AUTOSAR XML (schema 4-2-1)
standard types defined: boolean, uint16, uint32, uint8
package /VehicleProject
  system System
package /TP
  can tp config FD1_CAN: communication-cluster=FD1_CAN, can-tp-ecu{cycle-time-main-function=0.005, ecu-instance=PSCM_FD}
    can tp channel TPCH: channel-id=0, channel-mode=FULL-DUPLEX-MODE
    can-tp-connection addressing-format=STANDARD, can-tp-channel=TPCH, data-pdu=TesterFunctionalReq_FD1_Tp_oFD1_CAN, receiver=TN_PSCM_FD_FD, ta-type=FUNCTIONAL-CAN-FD, tp-sdu=TesterFunctionalReq_FD1_oFD1_CAN, transmitter=TN_TSTR_FD:
      ident TesterFunctionalReq_FD1_FD_oTN_TSTR_FD
    can-tp-connection addressing-format=STANDARD, can-tp-channel=TPCH, data-pdu=TesterFunctionalReq_FD1_Tp_oFD1_CAN_20, receiver=TN_PSCM_FD, ta-type=FUNCTIONAL, tp-sdu=TesterFunctionalReq_FD1_oFD1_CAN_20, transmitter=TN_TSTR:
      ident TesterFunctionalReq_FD1_oTN_TSTR
    can-tp-connection addressing-format=STANDARD, can-tp-channel=TPCH, data-pdu=TesterPhysicalReqPSCM_FD1_Tp_oFD1_CAN_20, flow-control-pdu=TesterPhysicalResPSCM_FD1_Tp_oFD1_CAN_20, receiver=TN_PSCM_FD, ta-type=PHYSICAL, tp-sdu=TesterPhysicalReqPSCM_FD1_oFD1_CAN_20, transmitter=TN_TSTR:
      ident TesterPhysicalReqPSCM_FD1_oTN_PSCM_FD
    can-tp-connection addressing-format=STANDARD, can-tp-channel=TPCH, data-pdu=TesterPhysicalReqPSCM_FD1_Tp_oFD1_CAN, flow-control-pdu=TesterPhysicalResPSCM_FD1_Tp_oFD1_CAN, receiver=TN_PSCM_FD_FD, ta-type=PHYSICAL-CAN-FD, tp-sdu=TesterPhysicalReqPSCM_FD1_oFD1_CAN, transmitter=TN_TSTR_FD:
      ident TesterPhysicalReqPSCM_FD1_oTN_PSCM_FD_FD
    can-tp-connection addressing-format=STANDARD, can-tp-channel=TPCH, data-pdu=TesterPhysicalResPSCM_FD1_Tp_oFD1_CAN_20, flow-control-pdu=TesterPhysicalReqPSCM_FD1_Tp_oFD1_CAN_20, receiver=TN_TSTR, ta-type=PHYSICAL, tp-sdu=TesterPhysicalResPSCM_FD1_oFD1_CAN_20, transmitter=TN_PSCM_FD:
      ident TesterPhysicalResPSCM_FD1_oTN_PSCM_FD
    can-tp-connection addressing-format=STANDARD, can-tp-channel=TPCH, data-pdu=TesterPhysicalResPSCM_FD1_Tp_oFD1_CAN, flow-control-pdu=TesterPhysicalReqPSCM_FD1_Tp_oFD1_CAN, receiver=TN_TSTR_FD, ta-type=PHYSICAL-CAN-FD, tp-sdu=TesterPhysicalResPSCM_FD1_oFD1_CAN, transmitter=TN_PSCM_FD_FD:
      ident TesterPhysicalResPSCM_FD1_oTN_PSCM_FD_FD
    4 x can tp node:
      TN_PSCM_FD: connector=CN_FD1_CAN
      TN_PSCM_FD_FD: connector=CN_FD1_CAN
      TN_TSTR
      TN_TSTR_FD
package /Cluster
  can cluster FD1_CAN: baudrate=500000, protocol-name=CAN, can-fd-baudrate=500000  # FD1_CAN_P702_GASD_MY21_V05 | New CAN FD network
    can physical channel CHNL: comm-connectors=CN_FD1_CAN
      frame ABS_BrkBst_Data_FD1_oFD1_CAN: id 0x4B0, to PSCM_FD, frame-length=8, can-addressing-mode=STANDARD, can-frame-rx-behavior=ANY, can-frame-tx-behavior=CAN-FD
        pdu ABS_BrkBst_Data_FD1_oFD1_CAN: length=8, minimum-delay=0.01, transmission-mode-false-timing=cyclic-timing={time-offset=0, time-period=0.02}, transmission-mode-true-timing=cyclic-timing={time-offset=0, time-period=0.02}, unused-bit-pattern=0
          signal YawStabilityIndex_oABS_BrkBst_Data_FD1_oFD1_CAN: start 0, 9 bit, big-endian, init-value=256, base-type=uint16, compu {510=Cx1FE_NoDataExists, 511=Cx1FF_Fault, phys=raw-256 for raw 0..511; unit %}, unit=%, transfer-property=PENDING, to PSCM_FD
      frame ActiveFrontStrg_Stat2_FD1_oFD1_CAN: id 0x8A, to PSCM_FD, frame-length=8, can-addressing-mode=STANDARD, can-frame-rx-behavior=ANY, can-frame-tx-behavior=CAN-FD
        pdu ActiveFrontStrg_Stat2_FD1_oFD1_CAN: length=8, minimum-delay=0.02, unused-bit-pattern=0
          signal SteWhlRelCalib_An_Sns_oActiveFrontStrg_Stat2_FD1_oFD1_CAN: start 15, 15 bit, big-endian, init-value=0, base-type=uint16, compu {32766=Cx7FFE_NoDataExists, 32767=Cx7FFF_Fault, phys=raw*0.1-1600 for raw 0..32767; unit deg} "Source signal range: [0,32765]", unit=deg, transfer-property=PENDING, to PSCM_FD  # Signal is not transmitted on vehicles where PSCM is transmitting the message that contains this signal. Signal data set to 0x0 for ABS only vehicle option content
      frame APIM_Send_Signals_2_FD1_oFD1_CAN: id 0x215, to PSCM_FD, frame-length=8, can-addressing-mode=STANDARD, can-frame-rx-behavior=ANY, can-frame-tx-behavior=CAN-FD
        pdu APIM_Send_Signals_2_FD1_oFD1_CAN: length=8, minimum-delay=0.02, unused-bit-pattern=0
          signal TrlrAidMde_D_Rq_oAPIM_Send_Signals_2_FD1_oFD1_CAN: start 5, 2 bit, big-endian, init-value=0, base-type=uint8, compu {0..3=RANGE, 0=Cx0_NoRequest, 1=Cx1_Mode_1, 2=Cx2_Mode_2, 3=Cx3_Mode_3; unit SED}, unit=SED, transfer-property=PENDING, to PSCM_FD
      frame APIM_Send_Signals1_FD1_oFD1_CAN: id 0x3F1, to PSCM_FD, frame-length=8, can-addressing-mode=STANDARD, can-frame-rx-behavior=ANY, can-frame-tx-behavior=CAN-FD  # APIM Tx
        pdu APIM_Send_Signals1_FD1_oFD1_CAN: length=8, minimum-delay=0.02, unused-bit-pattern=0
          signal TrlrAidCancl_B_Rq_oAPIM_Send_Signals1_FD1_oFD1_CAN: start 48, 1 bit, big-endian, init-value=0, base-type=boolean, compu {0..1=RANGE, 0=Cx0_Null, 1=Cx1_Cancel; unit SED}, unit=SED, transfer-property=PENDING, to PSCM_FD
      frame Body_Info_4_FD1_oFD1_CAN: id 0x242, to PSCM_FD, frame-length=8, can-addressing-mode=STANDARD, can-frame-rx-behavior=ANY, can-frame-tx-behavior=CAN-FD
        pdu Body_Info_4_FD1_oFD1_CAN: length=8, minimum-delay=0.02, unused-bit-pattern=0
          signal BattULo_U_Actl_oBody_Info_4_FD1_oFD1_CAN: start 39, 8 bit, big-endian, init-value=255, base-type=uint8, compu {255=CxFF_Fault, phys=raw*0.0625 for raw 0..255; unit volt} "Source signal range: [0,254]", unit=volt, transfer-property=PENDING, to PSCM_FD
      frame BodyInfo_3_FD1_oFD1_CAN: id 0x3B3, to PSCM_FD, frame-length=8, can-addressing-mode=STANDARD, can-frame-rx-behavior=ANY, can-frame-tx-behavior=CAN-FD
        pdu BodyInfo_3_FD1_oFD1_CAN: length=8, minimum-delay=0.02, unused-bit-pattern=0
          signal Ignition_Status_oBodyInfo_3_FD1_oFD1_CAN: start 7, 4 bit, big-endian, init-value=0, base-type=uint8, compu {0..15=RANGE, 0=Cx0_Unknown, 1=Cx1_Off, 2=Cx2_Accessory, 4=Cx4_Run, 8=Cx8_Start, 15=CxF_Invalid; unit SED}, unit=SED, transfer-property=PENDING, to PSCM_FD
          signal LifeCycMde_D_Actl_oBodyInfo_3_FD1_oFD1_CAN: start 53, 4 bit, big-endian, init-value=0, base-type=uint8, compu {0..15=RANGE, 0=Cx0_Normal, 1=Cx1_Factory, 2=Cx2_NotUsed, 3=Cx3_Transport; unit SED}, unit=SED, transfer-property=PENDING, to PSCM_FD
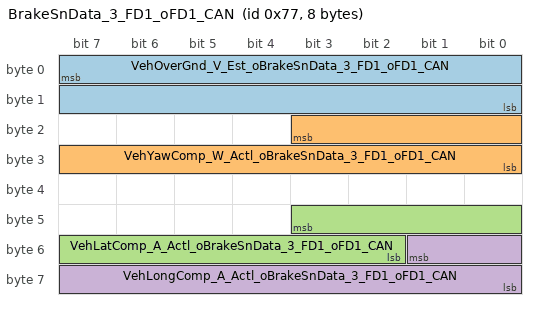
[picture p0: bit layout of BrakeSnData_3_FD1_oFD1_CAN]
      frame BrakeSnData_3_FD1_oFD1_CAN: id 0x77, to PSCM_FD, frame-length=8, can-addressing-mode=STANDARD, can-frame-rx-behavior=ANY, can-frame-tx-behavior=CAN-FD
        pdu BrakeSnData_3_FD1_oFD1_CAN: length=8, minimum-delay=0.01, transmission-mode-false-timing=cyclic-timing={time-offset=0, time-period=0.02}, transmission-mode-true-timing=cyclic-timing={time-offset=0, time-period=0.02}, unused-bit-pattern=0
          signal VehOverGnd_V_Est_oBrakeSnData_3_FD1_oFD1_CAN: start 7, 16 bit, big-endian, init-value=0, base-type=uint16, compu {65534=CxFFFE_Unknown, 65535=CxFFFF_Invalid, phys=raw*0.01 for raw 0..65535; unit kph} "Source signal range: [0,65533]", unit=kph, transfer-property=PENDING, to PSCM_FD
          signal VehYawComp_W_Actl_oBrakeSnData_3_FD1_oFD1_CAN: start 19, 12 bit, big-endian, init-value=4094, base-type=uint16, compu {4094=CxFFE_NoDataExists, 4095=CxFFF_Fault, phys=raw*0.03663-75 for raw 0..4095; unit deg/s} "Source signal range: [0,4093]", unit=deg/s, transfer-property=PENDING, to PSCM_FD
          signal VehLatComp_A_Actl_oBrakeSnData_3_FD1_oFD1_CAN: start 43, 10 bit, big-endian, init-value=1022, base-type=uint16, compu {1022=Cx3FE_NoDataExists, 1023=Cx3FF_Fault, phys=raw*0.035-17.9 for raw 0..1023; unit m/s^2} "Source signal range: [0,1021]", unit=m/s^2, transfer-property=PENDING, to PSCM_FD
          signal VehLongComp_A_Actl_oBrakeSnData_3_FD1_oFD1_CAN: start 49, 10 bit, big-endian, init-value=1022, base-type=uint16, compu {1022=Cx3FE_NoDataExists, 1023=Cx3FF_Fault, phys=raw*0.035-17.9 for raw 0..1023; unit m/s^2} "Source signal range: [0,1021]", unit=m/s^2, transfer-property=PENDING, to PSCM_FD
      frame BrakeSnData_4_FD1_oFD1_CAN: id 0x7D, to PSCM_FD, frame-length=8, can-addressing-mode=STANDARD, can-frame-rx-behavior=ANY, can-frame-tx-behavior=CAN-FD
        pdu BrakeSnData_4_FD1_oFD1_CAN: length=8, minimum-delay=0.01, transmission-mode-false-timing=cyclic-timing={time-offset=0, time-period=0.02}, transmission-mode-true-timing=cyclic-timing={time-offset=0, time-period=0.02}, unused-bit-pattern=0
          signal BrkTot_Tq_Actl_oBrakeSnData_4_FD1_oFD1_CAN: start 27, 13 bit, big-endian, init-value=0, base-type=uint16, compu {8190=Cx1FFE_Unknown, 8191=Cx1FFF_Fault, phys=raw*4 for raw 0..8191; unit Nm} "Source signal range: [0,8189]", unit=Nm, transfer-property=PENDING, to PSCM_FD
          signal VehVertComp_A_Actl_oBrakeSnData_4_FD1_oFD1_CAN: start 45, 10 bit, big-endian, init-value=1022, base-type=uint16, compu {1022=Cx3FE_NoDataExists, 1023=Cx3FF_Fault, phys=raw*0.035-17.9 for raw 0..1023; unit m/s^2} "Source signal range: [0,1021]", unit=m/s^2, transfer-property=PENDING, to PSCM_FD
      frame BrakeSnData_5_FD1_oFD1_CAN: id 0x76, to PSCM_FD, frame-length=8, can-addressing-mode=STANDARD, can-frame-rx-behavior=ANY, can-frame-tx-behavior=CAN-FD
        pdu BrakeSnData_5_FD1_oFD1_CAN: length=8, minimum-delay=0.02, transmission-mode-false-timing={cyclic-timing={time-offset=0, time-period=0.5}, event-controlled-timing={number-of-repetitions=0, repetition-period=0}}, transmission-mode-true-timing={cyclic-timing={time-offset=0, time-period=0.5}, event-controlled-timing={number-of-repetitions=0, repetition-period=0}}, unused-bit-pattern=0
          signal DrvSte_D_Stat_oBrakeSnData_5_FD1_oFD1_CAN: start 19, 4 bit, big-endian, init-value=0, base-type=uint8, compu {0..15=RANGE, 0=Cx0_DSR_Deactivated, 1=Cx1_DSR_Request_Not_Applicable, 2=Cx2_EPAS_Comm_Disturbed, 3=Cx3_DSR_in_Normal_Idle_Mode, 4=Cx4_Ignition_Off, 5=Cx5_Request_Active, 6=Cx6_NotUsed1, 7=Cx7_NotUsed2, 8=Cx8_NotUsed3, 9=Cx9_NotUsed4, 10=CxA_NotUsed5, 11=CxB_NotUsed6, 12=CxC_NotUsed7, 13=CxD_NotUsed8, 14=CxE_NotUsed9, 15=CxF_NotUsed10; unit SED}, unit=SED, transfer-property=TRIGGERED-ON-CHANGE-WITHOUT-REPETITION, to PSCM_FD
          signal DrvSte_Tq_Rq_oBrakeSnData_5_FD1_oFD1_CAN: start 31, 8 bit, big-endian, init-value=128, base-type=uint8, compu {254=CxFE_Unknown, 255=CxFF_Invalid, phys=raw*0.0625-8 for raw 0..255; unit Nm} "Source signal range: [0,253]", unit=Nm, transfer-property=PENDING, to PSCM_FD
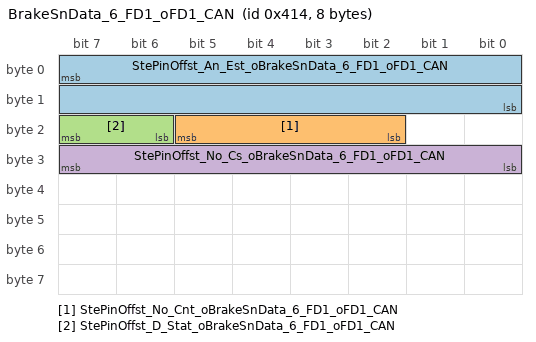
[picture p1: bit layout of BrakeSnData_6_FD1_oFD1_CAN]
      frame BrakeSnData_6_FD1_oFD1_CAN: id 0x414, to PSCM_FD, frame-length=8, can-addressing-mode=STANDARD, can-frame-rx-behavior=ANY, can-frame-tx-behavior=CAN-FD
        pdu BrakeSnData_6_FD1_oFD1_CAN: length=8, minimum-delay=0.02, transmission-mode-false-timing=cyclic-timing={time-offset=0, time-period=0.1}, transmission-mode-true-timing=cyclic-timing={time-offset=0, time-period=0.1}, unused-bit-pattern=0
          signal StePinOffst_An_Est_oBrakeSnData_6_FD1_oFD1_CAN: start 7, 16 bit, big-endian, init-value=65534, base-type=uint16, compu {65534=CxFFFE_NoDataExists, 65535=CxFFFF_Faulty, phys=raw*0.1-3200 for raw 0..65535; unit degrees} "Source signal range: [0,65533]", unit=degrees, transfer-property=PENDING, to PSCM_FD  # SASM will transmit these signals on vehicles with SASM and without PSCM. SCCM will not Tx this signal when SASM is present.
          signal StePinOffst_No_Cnt_oBrakeSnData_6_FD1_oFD1_CAN: start 21, 4 bit, big-endian, init-value=0, base-type=uint8, compu {0..15=RANGE; unit unitless}, unit=unitless, transfer-property=PENDING, to PSCM_FD
          signal StePinOffst_D_Stat_oBrakeSnData_6_FD1_oFD1_CAN: start 23, 2 bit, big-endian, init-value=0, base-type=uint8, compu {0..3=RANGE, 0=Cx0_OffsetNotCalculated, 1=Cx1_StoredOffset, 2=Cx2_CoarseOffset, 3=Cx3_FineOffset; unit SED}, unit=SED, transfer-property=PENDING, to PSCM_FD
          signal StePinOffst_No_Cs_oBrakeSnData_6_FD1_oFD1_CAN: start 31, 8 bit, big-endian, init-value=0, base-type=uint8, compu {0..255=RANGE; unit Unitless}, unit=Unitless, transfer-property=PENDING, to PSCM_FD  # Signal not transmitted on gas variants.
      frame BrakeSysFeatures_3_oFD1_CAN: id 0x41E, to PSCM_FD, frame-length=8, can-addressing-mode=STANDARD, can-frame-rx-behavior=ANY, can-frame-tx-behavior=CAN-FD
        pdu BrakeSysFeatures_3_oFD1_CAN: length=8, minimum-delay=0.02, transmission-mode-false-timing={cyclic-timing={time-offset=0, time-period=1}, event-controlled-timing={number-of-repetitions=0, repetition-period=0}}, transmission-mode-true-timing={cyclic-timing={time-offset=0, time-period=1}, event-controlled-timing={number-of-repetitions=0, repetition-period=0}}, unused-bit-pattern=0
          signal SelDrvMdeChassis2_D_Rq_oBrakeSysFeatures_3_oFD1_CAN: start 45, 5 bit, big-endian, init-value=0, base-type=uint8, compu {0..31=RANGE, 0=Cx00_NormalMode, 1=Cx01_NormalAdaptiveMode, 2=Cx02_EconomyMode, 3=Cx03_SportMode, 4=Cx04_SportAdaptiveMode, 5=Cx05_ComfortMode, 6=Cx06_ComfortAdaptiveMode, 7=Cx07_LowMuMode, 8=Cx08_MudAndRutsMode, 9=Cx09_SandMode, 10=Cx0A_RockCrawlMode, 11=Cx0B_TowHaulMode, 12=Cx0C_HighSpeedDesertMode, 13=Cx0D_TrackMode, 14=Cx0E_RoughRoadMode, 15=Cx0F_NotUsed2, 16=Cx10_NotUsed3, 17=Cx11_NotUsed4, 18=Cx12_NotUsed5, 19=Cx13_NotUsed6, 20=Cx14_NotUsed7, 21=Cx15_NotUsed8, 22=Cx16_NotUsed9, 23=Cx17_NotUsed10, 24=Cx18_NotUsed11, 25=Cx19_NotUsed12, 26=Cx1A_NotUsed13, 27=Cx1B_NotUsed14, 28=Cx1C_NotUsed15, 29=Cx1D_NotUsed16, 30=Cx1E_NotUsed17, 31=Cx1F_Faulty; unit SED}, unit=SED, transfer-property=TRIGGERED-ON-CHANGE-WITHOUT-REPETITION, to PSCM_FD
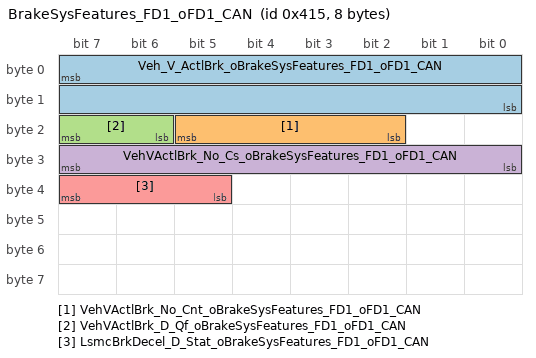
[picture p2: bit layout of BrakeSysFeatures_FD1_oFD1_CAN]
      frame BrakeSysFeatures_FD1_oFD1_CAN: id 0x415, to PSCM_FD, frame-length=8, can-addressing-mode=STANDARD, can-frame-rx-behavior=ANY, can-frame-tx-behavior=CAN-FD
        pdu BrakeSysFeatures_FD1_oFD1_CAN: length=8, minimum-delay=0.01, transmission-mode-false-timing=cyclic-timing={time-offset=0, time-period=0.02}, transmission-mode-true-timing=cyclic-timing={time-offset=0, time-period=0.02}, unused-bit-pattern=0
          signal Veh_V_ActlBrk_oBrakeSysFeatures_FD1_oFD1_CAN: start 7, 16 bit, big-endian, init-value=0, base-type=uint16, compu {phys=raw*0.01 for raw 0..65535; unit kph}, unit=kph, transfer-property=PENDING, to PSCM_FD
          signal VehVActlBrk_No_Cnt_oBrakeSysFeatures_FD1_oFD1_CAN: start 21, 4 bit, big-endian, init-value=0, base-type=uint8, compu {0..15=RANGE; unit Unitless}, unit=Unitless, transfer-property=PENDING, to PSCM_FD
          signal VehVActlBrk_D_Qf_oBrakeSysFeatures_FD1_oFD1_CAN: start 23, 2 bit, big-endian, init-value=0, base-type=uint8, compu {0..3=RANGE, 0=Cx0_Faulty, 1=Cx1_No_Data_Exists, 2=Cx2_Not_Within_Specifications, 3=Cx3_OK; unit SED}, unit=SED, transfer-property=PENDING, to PSCM_FD
          signal VehVActlBrk_No_Cs_oBrakeSysFeatures_FD1_oFD1_CAN: start 31, 8 bit, big-endian, init-value=0, base-type=uint8, compu {0..255=RANGE; unit Unitless}, unit=Unitless, transfer-property=PENDING, to PSCM_FD
          signal LsmcBrkDecel_D_Stat_oBrakeSysFeatures_FD1_oFD1_CAN: start 39, 3 bit, big-endian, init-value=0, base-type=uint8, compu {0..7=RANGE, 0=Cx0_Off, 1=Cx1_On, 2=Cx2_FaultExt, 3=Cx3_FaultDegraded, 4=Cx4_Denied, 5=Cx5_NotUsed_1, 6=Cx6_NotUsed_2, 7=Cx7_NotUsed_3; unit SED}, unit=SED, transfer-property=PENDING, to PSCM_FD
      frame Climate_Control_Data_FD1_oFD1_CAN: id 0x41A, to PSCM_FD, frame-length=8, can-addressing-mode=STANDARD, can-frame-rx-behavior=ANY, can-frame-tx-behavior=CAN-FD
        pdu Climate_Control_Data_FD1_oFD1_CAN: length=8, minimum-delay=0.02, unused-bit-pattern=0
          signal Outside_Air_Temp_Stat_oClimate_Control_Data_FD1_oFD1_CAN: start 7, 8 bit, big-endian, init-value=254, base-type=uint8, compu {254=CxFE_Unknown, 255=CxFF_Invalid, phys=raw*0.5-40 for raw 0..255; unit Degrees C} "Source signal range: [0,253]", unit=Degrees C, transfer-property=PENDING, to PSCM_FD  # Filtered value, i.e. same as disply for customer
      frame Cluster_Info1_FD1_oFD1_CAN: id 0x430, to PSCM_FD, frame-length=8, can-addressing-mode=STANDARD, can-frame-rx-behavior=ANY, can-frame-tx-behavior=CAN-FD
        pdu Cluster_Info1_FD1_oFD1_CAN: length=8, minimum-delay=0.02, unused-bit-pattern=0
          signal OdometerMasterValue_oCluster_Info1_FD1_oFD1_CAN: start 15, 24 bit, big-endian, init-value=0, base-type=uint32, compu {0..16777215=RANGE, 16777215=CxFFFFFF_Invalid; unit km} "Source signal range: [0,16777214]", unit=km, transfer-property=PENDING, to PSCM_FD
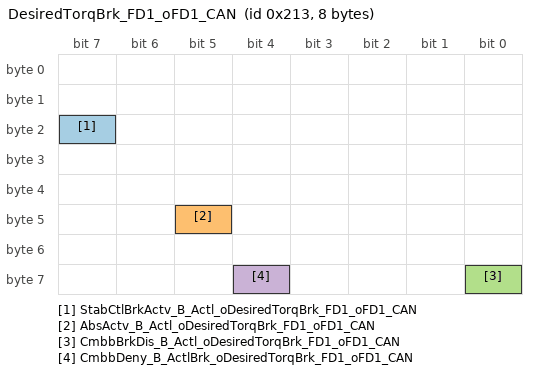
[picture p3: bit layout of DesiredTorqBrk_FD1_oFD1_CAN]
      frame DesiredTorqBrk_FD1_oFD1_CAN: id 0x213, to PSCM_FD, frame-length=8, can-addressing-mode=STANDARD, can-frame-rx-behavior=ANY, can-frame-tx-behavior=CAN-FD  # When PBM is present use 0x41B for PrkMsgTxt_D_Rq, PrkBrkRedLamp_D_Rq, PrkBrkYwLamp_D_Rq source signals otherwise ABS will source from 0x213.
        pdu DesiredTorqBrk_FD1_oFD1_CAN: length=8, minimum-delay=0.01, transmission-mode-false-timing=cyclic-timing={time-offset=0, time-period=0.02}, transmission-mode-true-timing=cyclic-timing={time-offset=0, time-period=0.02}, unused-bit-pattern=0
          signal StabCtlBrkActv_B_Actl_oDesiredTorqBrk_FD1_oFD1_CAN: start 23, 1 bit, big-endian, init-value=0, base-type=boolean, compu {0..1=RANGE, 0=Cx0_No, 1=Cx1_Yes; unit SED}, unit=SED, transfer-property=PENDING, to PSCM_FD
          signal AbsActv_B_Actl_oDesiredTorqBrk_FD1_oFD1_CAN: start 45, 1 bit, big-endian, init-value=0, base-type=boolean, compu {0..1=RANGE, 0=Cx0_No, 1=Cx1_Yes; unit SED}, unit=SED, transfer-property=PENDING, to PSCM_FD
          signal CmbbBrkDis_B_Actl_oDesiredTorqBrk_FD1_oFD1_CAN: start 56, 1 bit, big-endian, init-value=0, base-type=boolean, compu {0..1=RANGE, 0=Cx0_No, 1=Cx1_Yes; unit SED}, unit=SED, transfer-property=PENDING, to PSCM_FD
          signal CmbbDeny_B_ActlBrk_oDesiredTorqBrk_FD1_oFD1_CAN: start 60, 1 bit, big-endian, init-value=0, base-type=boolean, compu {0..1=RANGE, 0=Cx0_No, 1=Cx1_Yes; unit SED}, unit=SED, transfer-property=PENDING, to PSCM_FD
      frame EngBrakeData_FD1_oFD1_CAN: id 0x165, to PSCM_FD, frame-length=8, can-addressing-mode=STANDARD, can-frame-rx-behavior=ANY, can-frame-tx-behavior=CAN-FD
        pdu EngBrakeData_FD1_oFD1_CAN: length=8, minimum-delay=0.01, transmission-mode-false-timing=cyclic-timing={time-offset=0, time-period=0.02}, transmission-mode-true-timing=cyclic-timing={time-offset=0, time-period=0.02}, unused-bit-pattern=0
          signal BpedDrvAppl_D_Actl_oEngBrakeData_FD1_oFD1_CAN: start 5, 2 bit, big-endian, init-value=1, base-type=uint8, compu {0..3=RANGE, 0=Cx0_Not_Allowed, 1=Cx1_Driver_Not_Braking, 2=Cx2_Driver_Braking, 3=Cx3_Not_Allowed; unit SED}, unit=SED, transfer-property=PENDING, to PSCM_FD  # CCMGenSigTimeoutTime=1000
          signal BPedDrvAppl_D_QF_oEngBrakeData_FD1_oFD1_CAN: start 15, 2 bit, big-endian, init-value=1, base-type=uint8, compu {0..3=RANGE, 0=Cx0_Faulty, 1=Cx1_No_Data_Exists, 2=Cx2_Not_Within_Specifications, 3=Cx3_OK; unit SED}, unit=SED, transfer-property=PENDING, to PSCM_FD
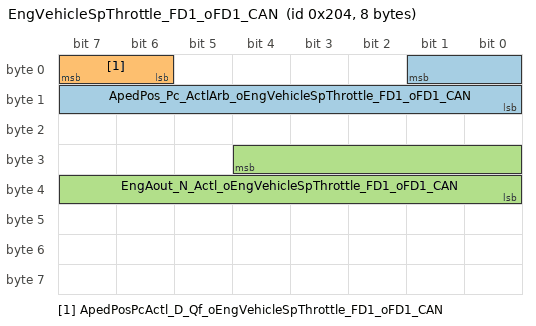
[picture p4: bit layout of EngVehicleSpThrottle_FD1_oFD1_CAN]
      frame EngVehicleSpThrottle_FD1_oFD1_CAN: id 0x204, to PSCM_FD, frame-length=8, can-addressing-mode=STANDARD, can-frame-rx-behavior=ANY, can-frame-tx-behavior=CAN-FD
        pdu EngVehicleSpThrottle_FD1_oFD1_CAN: length=8, minimum-delay=0, transmission-mode-false-timing=cyclic-timing={time-offset=0, time-period=0.01}, transmission-mode-true-timing=cyclic-timing={time-offset=0, time-period=0.01}, unused-bit-pattern=0
          signal ApedPos_Pc_ActlArb_oEngVehicleSpThrottle_FD1_oFD1_CAN: start 1, 10 bit, big-endian, init-value=0, base-type=uint16, compu {phys=raw*0.1 for raw 0..1022; unit %}, unit=%, transfer-property=PENDING, to PSCM_FD  # ABSGenSigTimeoutTime=1000
          signal ApedPosPcActl_D_Qf_oEngVehicleSpThrottle_FD1_oFD1_CAN: start 7, 2 bit, big-endian, init-value=1, base-type=uint8, compu {0..3=RANGE, 0=Cx0_Faulty, 1=Cx1_No_Data_Exists, 2=Cx2_Not_Within_Specifications, 3=Cx3_OK; unit SED}, unit=SED, transfer-property=PENDING, to PSCM_FD
          signal EngAout_N_Actl_oEngVehicleSpThrottle_FD1_oFD1_CAN: start 28, 13 bit, big-endian, init-value=0, base-type=uint16, compu {phys=raw*2 for raw 0..8191; unit rpm}, unit=rpm, transfer-property=PENDING, to PSCM_FD
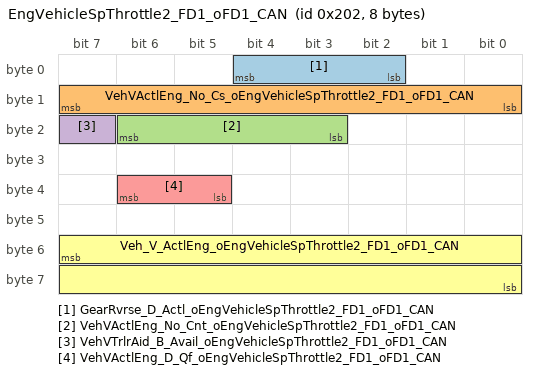
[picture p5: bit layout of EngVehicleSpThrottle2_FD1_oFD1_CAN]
      frame EngVehicleSpThrottle2_FD1_oFD1_CAN: id 0x202, to PSCM_FD, frame-length=8, can-addressing-mode=STANDARD, can-frame-rx-behavior=ANY, can-frame-tx-behavior=CAN-FD
        pdu EngVehicleSpThrottle2_FD1_oFD1_CAN: length=8, minimum-delay=0.01, transmission-mode-false-timing=cyclic-timing={time-offset=0, time-period=0.02}, transmission-mode-true-timing=cyclic-timing={time-offset=0, time-period=0.02}, unused-bit-pattern=0
          signal GearRvrse_D_Actl_oEngVehicleSpThrottle2_FD1_oFD1_CAN: start 4, 3 bit, big-endian, init-value=7, base-type=uint8, compu {0..7=RANGE, 0=Cx0_Inactive_not_confirmed, 1=Cx1_Inactive_confirmed, 2=Cx2_Active_not_confirmed, 3=Cx3_Active_confirmed, 4=Cx4_NotUsed_1, 5=Cx5_NotUsed_2, 6=Cx6_NotUsed_3, 7=Cx7_Fault; unit SED}, unit=SED, transfer-property=PENDING, to PSCM_FD  # Do not implement GearRvrse_D_Actl until eTracker 8804151 is approved, 11/24/09
          signal VehVActlEng_No_Cs_oEngVehicleSpThrottle2_FD1_oFD1_CAN: start 15, 8 bit, big-endian, init-value=0, base-type=uint8, compu {0..255=RANGE; unit Unitless}, unit=Unitless, transfer-property=PENDING, to PSCM_FD
          signal VehVActlEng_No_Cnt_oEngVehicleSpThrottle2_FD1_oFD1_CAN: start 22, 4 bit, big-endian, init-value=0, base-type=uint8, compu {0..15=RANGE; unit Unitless}, unit=Unitless, transfer-property=PENDING, to PSCM_FD
          signal VehVTrlrAid_B_Avail_oEngVehicleSpThrottle2_FD1_oFD1_CAN: start 23, 1 bit, big-endian, init-value=0, base-type=boolean, compu {0..1=RANGE, 0=Cx0_No, 1=Cx1_Yes; unit SED}, unit=SED, transfer-property=PENDING, to PSCM_FD
          signal VehVActlEng_D_Qf_oEngVehicleSpThrottle2_FD1_oFD1_CAN: start 38, 2 bit, big-endian, init-value=0, base-type=uint8, compu {0..3=RANGE, 0=Cx0_Faulty, 1=Cx1_No_Data_Exists, 2=Cx2_Not_Within_Specifications, 3=Cx3_OK; unit SED}, unit=SED, transfer-property=PENDING, to PSCM_FD
          signal Veh_V_ActlEng_oEngVehicleSpThrottle2_FD1_oFD1_CAN: start 55, 16 bit, big-endian, init-value=0, base-type=uint16, compu {phys=raw*0.01 for raw 0..65535; unit kph}, unit=kph, transfer-property=PENDING, to PSCM_FD
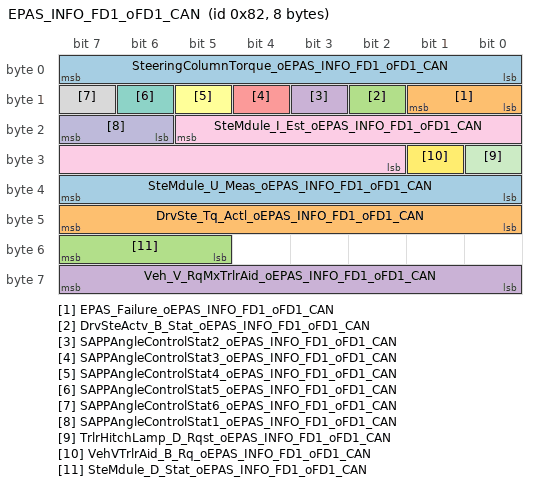
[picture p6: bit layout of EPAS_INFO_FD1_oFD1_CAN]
      frame EPAS_INFO_FD1_oFD1_CAN: id 0x82, from PSCM_FD, frame-length=8, variation-point=post-build-variant-condition{matching-criterion=Communication, value=0}, can-addressing-mode=STANDARD, can-frame-rx-behavior=ANY, can-frame-tx-behavior=CAN-FD  # drecker 10/23/09 Need SAPP in sync w/Strg Torque for proper PAM interpretation, else fault msg's displayed FP@20ms IPC needs EPAS_Failure for msg to driver. Not map w/Lane Assist FP@30s FP), save bandwidth if feature not on vehicle
        pdu EPAS_INFO_FD1_oFD1_CAN: length=8, minimum-delay=0.01, transmission-mode-false-timing=cyclic-timing={time-offset=0, time-period=0.02}, transmission-mode-true-timing=cyclic-timing={time-offset=0, time-period=0.02}, unused-bit-pattern=0
          signal SteeringColumnTorque_oEPAS_INFO_FD1_oFD1_CAN: start 7, 8 bit, big-endian, init-value=254, base-type=uint8, compu {254=CxFE_Unknown, 255=CxFF_Invalid, phys=raw*0.0625-8 for raw 0..255; unit Nm} "Source signal range: [0,253]", unit=Nm, transfer-property=PENDING
          signal EPAS_Failure_oEPAS_INFO_FD1_oFD1_CAN: start 9, 2 bit, big-endian, init-value=0, base-type=uint8, compu {0..3=RANGE, 0=Cx0_EPAS_OK_NO_MESSAGE, 1=Cx1_POWER_STRG_ASSIST_FAULT, 2=Cx2_SERVICE_POWER_STEERING, 3=Cx3_SERVICE_POWER_STEERING_NOW; unit SED}, unit=SED, transfer-property=PENDING
          signal DrvSteActv_B_Stat_oEPAS_INFO_FD1_oFD1_CAN: start 10, 1 bit, big-endian, init-value=0, base-type=boolean, compu {0..1=RANGE, 0=Cx0_Inactive, 1=Cx1_Active; unit SED}, unit=SED, transfer-property=PENDING
          signal SAPPAngleControlStat2_oEPAS_INFO_FD1_oFD1_CAN: start 11, 1 bit, big-endian, init-value=0, base-type=boolean, compu {0..1=RANGE, 0=Cx0_NoRel_ExtSteeringAngleReqx, 1=Cx1_Rel_ExtSteeringAngleReqx; unit SED}, unit=SED, transfer-property=PENDING
          signal SAPPAngleControlStat3_oEPAS_INFO_FD1_oFD1_CAN: start 12, 1 bit, big-endian, init-value=0, base-type=boolean, compu {0..1=RANGE, 0=Cx0_ExternalSigContentOKforEAC, 1=Cx1_EARactiveNoReverseEngage; unit SED}, unit=SED, transfer-property=PENDING
          signal SAPPAngleControlStat4_oEPAS_INFO_FD1_oFD1_CAN: start 13, 1 bit, big-endian, init-value=0, base-type=boolean, compu {0..1=RANGE, 0=Cx0_ExternalSigContentOKforEAC, 1=Cx1_SpeedLimitExceededEAROn; unit SED}, unit=SED, transfer-property=PENDING
          signal SAPPAngleControlStat5_oEPAS_INFO_FD1_oFD1_CAN: start 14, 1 bit, big-endian, init-value=0, base-type=boolean, compu {0..1=RANGE, 0=Cx0_ExternalSigContentOKforEAC, 1=Cx1_StrgColTorqueExceed_EAROn; unit SED}, unit=SED, transfer-property=PENDING
          signal SAPPAngleControlStat6_oEPAS_INFO_FD1_oFD1_CAN: start 15, 1 bit, big-endian, init-value=0, base-type=boolean, compu {0..1=RANGE, 0=Cx0_RequestedAngleCanBeReached, 1=Cx1_RequestedAngleNotReached; unit SED}, unit=SED, transfer-property=PENDING
          signal SteMdule_I_Est_oEPAS_INFO_FD1_oFD1_CAN: start 21, 12 bit, big-endian, init-value=4095, base-type=uint16, compu {4095=CxFFF_Invalid, phys=raw*0.05-64 for raw 0..4095; unit Amps} "Source signal range: [0,4094]", unit=Amps, transfer-property=PENDING  # DCR 1745 to update Tx from GWM to EP100ms. SteMdule_I_Est & SteMdule_U_Meas are used by BMS system & filtered. The filter uses standard periodic rate & changing to EP would adversely affect the filter.(jweinfur)
          signal SAPPAngleControlStat1_oEPAS_INFO_FD1_oFD1_CAN: start 23, 2 bit, big-endian, init-value=0, base-type=uint8, compu {0..3=RANGE, 0=Cx0_Closed, 1=Cx1_Open, 2=Cx2_Active, 3=Cx3_Fault; unit SED}, unit=SED, transfer-property=PENDING
          signal TrlrHitchLamp_D_Rqst_oEPAS_INFO_FD1_oFD1_CAN: start 24, 1 bit, big-endian, init-value=0, base-type=boolean, compu {0..1=RANGE, 0=Cx0_Off, 1=Cx1_On; unit SED}, unit=SED, transfer-property=PENDING
          signal VehVTrlrAid_B_Rq_oEPAS_INFO_FD1_oFD1_CAN: start 25, 1 bit, big-endian, init-value=0, base-type=boolean, compu {0..1=RANGE, 0=Cx0_NoRequest, 1=Cx1_Request; unit SED}, unit=SED, transfer-property=PENDING  # VR session start- req. limit blower speed no more than X volts. CC restriction on time msg. will be honored.Double Event msg1st event to request limit, 2nd event to release limit, No msg. CC Grammar v7.xls
          signal SteMdule_U_Meas_oEPAS_INFO_FD1_oFD1_CAN: start 39, 8 bit, big-endian, init-value=255, base-type=uint8, compu {255=CxFF_Invalid, phys=raw*0.05+6 for raw 0..255; unit Volts} "Source signal range: [0,254]", unit=Volts, transfer-property=PENDING  # DCR 1745 to update Tx from GWM to EP100ms. SteMdule_I_Est & SteMdule_U_Meas are used by BMS system & filtered. The filter uses standard periodic rate & changing to EP would adversely affect the filter.(jweinfur)
          signal DrvSte_Tq_Actl_oEPAS_INFO_FD1_oFD1_CAN: start 47, 8 bit, big-endian, init-value=128, base-type=uint8, compu {254=CxFE_Unknown, 255=CxFF_Invalid, phys=raw*0.0625-8 for raw 0..255; unit Nm} "Source signal range: [0,253]", unit=Nm, transfer-property=PENDING
          signal SteMdule_D_Stat_oEPAS_INFO_FD1_oFD1_CAN: start 55, 3 bit, big-endian, init-value=0, base-type=uint8, compu {0..7=RANGE, 0=Cx0_EPAS_Initialization, 1=Cx1_Normal_Op_Limited_Assist, 2=Cx2_Normal_Op_Full_Assist, 3=Cx3_EPAS_Shutdown, 4=Cx4_System_Failure, 5=Cx5_EPAS_Failure2, 6=Cx6_EPAS_Failure3, 7=Cx7_NotUsed; unit SED}, unit=SED, transfer-property=PENDING
          signal Veh_V_RqMxTrlrAid_oEPAS_INFO_FD1_oFD1_CAN: start 63, 8 bit, big-endian, init-value=255, base-type=uint8, compu {phys=raw*0.1 for raw 0..255; unit km/h}, unit=km/h, transfer-property=PENDING
      frame GGCC_Config_Mgmt_ID_1_FD1_oFD1_CAN: id 0x40A, to PSCM_FD, frame-length=8, can-addressing-mode=STANDARD, can-frame-rx-behavior=ANY, can-frame-tx-behavior=CAN-FD
        pdu GGCC_Config_Mgmt_ID_1_FD1_oFD1_CAN: length=8, minimum-delay=0.02, unused-bit-pattern=0
          signal VehicleGGCCData_oGGCC_Config_Mgmt_ID_1_FD1_oFD1_CAN: start 0, 64 bit, opaque, init-value=8 x 0, base-type=uint8_8_iso_8859_1, compu {0..18446744073709551615=RANGE; unit mixed}, unit=mixed, transfer-property=PENDING, to PSCM_FD  # RCMGenSigTimeout=6000
      frame Image_Processing_Data_FD1_oFD1_CAN: id 0x451, to PSCM_FD, frame-length=8, can-addressing-mode=STANDARD, can-frame-rx-behavior=ANY, can-frame-tx-behavior=CAN-FD
        pdu Image_Processing_Data_FD1_oFD1_CAN: length=8, minimum-delay=0.02, transmission-mode-false-timing={cyclic-timing={time-offset=0, time-period=1}, event-controlled-timing={number-of-repetitions=0, repetition-period=0}}, transmission-mode-true-timing={cyclic-timing={time-offset=0, time-period=1}, event-controlled-timing={number-of-repetitions=0, repetition-period=0}}, unused-bit-pattern=0
          signal TrlrRvrseEnbl_D2_Stat_oImage_Processing_Data_FD1_oFD1_CAN: start 18, 3 bit, big-endian, init-value=0, base-type=uint8, compu {0..7=RANGE, 0=Cx0_Inactive, 1=Cx1_TbaActive, 2=Cx2_TbaSetup, 3=Cx3_TbaOffTrgSetup, 4=Cx4_TbaOffTrgActive, 5=Cx5_TbaActiveExpertAvail, 6=Cx6_TbaActiveExpertActive, 7=Cx7_NotUsed; unit SED}, unit=SED, transfer-property=TRIGGERED-ON-CHANGE-WITHOUT-REPETITION, to PSCM_FD
          signal TrlrRvrseMsgTxt_D2_Rq_oImage_Processing_Data_FD1_oFD1_CAN: start 31, 6 bit, big-endian, init-value=0, base-type=uint8, compu {0..63=RANGE, 0=Cx00_NoMessage, 1=Cx01_Message1, 2=Cx02_Message2, 3=Cx03_Message3, 4=Cx04_Message4, 5=Cx05_Message5, 6=Cx06_Message6, 7=Cx07_Message7, 8=Cx08_Message8, 9=Cx09_Message9, 10=Cx0A_Message10, 11=Cx0B_Message11, 12=Cx0C_Message12, 13=Cx0D_Message13, 14=Cx0E_Message14, 15=Cx0F_Message15, 16=Cx10_Message16, 17=Cx11_Message17, 18=Cx12_Message18, 19=Cx13_Message19, 20=Cx14_Message20, 21=Cx15_Message21, 22=Cx16_Message22, 23=Cx17_Message23, 24=Cx18_Message24, 25=Cx19_Message25, 26=Cx1A_Message26, 27=Cx1B_Message27, 28=Cx1C_Message28, 29=Cx1D_Message29, 30=Cx1E_Message30, 31=Cx1F_Message31; unit SED}, unit=SED, transfer-property=TRIGGERED-ON-CHANGE-WITHOUT-REPETITION, to PSCM_FD
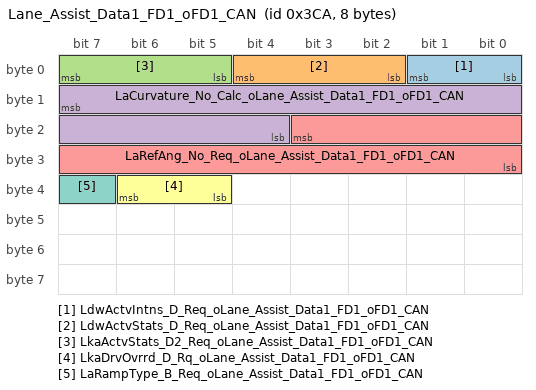
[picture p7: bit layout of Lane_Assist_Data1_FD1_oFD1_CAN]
      frame Lane_Assist_Data1_FD1_oFD1_CAN: id 0x3CA, to PSCM_FD, frame-length=8, can-addressing-mode=STANDARD, can-frame-rx-behavior=ANY, can-frame-tx-behavior=CAN-FD
        pdu Lane_Assist_Data1_FD1_oFD1_CAN: length=8, minimum-delay=0.01, unused-bit-pattern=0
          signal LdwActvIntns_D_Req_oLane_Assist_Data1_FD1_oFD1_CAN: start 1, 2 bit, big-endian, init-value=0, base-type=uint8, compu {0..3=RANGE, 0=Cx0_None, 1=Cx1_Low, 2=Cx2_Medium, 3=Cx3_High; unit SED}, unit=SED, transfer-property=PENDING, to PSCM_FD
          signal LdwActvStats_D_Req_oLane_Assist_Data1_FD1_oFD1_CAN: start 4, 3 bit, big-endian, init-value=0, base-type=uint8, compu {0..7=RANGE, 0=Cx0_LDW_Idle, 1=Cx1_Not_Used1, 2=Cx2_LDW_Warning_Left, 3=Cx3_LDW_Suppress_Left, 4=Cx4_LDW_Warning_Right, 5=Cx5_LDW_Suppress_Right, 6=Cx6_Not_Used2, 7=Cx7_LDW_Suppress_Right_Left; unit SED}, unit=SED, transfer-property=PENDING, to PSCM_FD
          signal LkaActvStats_D2_Req_oLane_Assist_Data1_FD1_oFD1_CAN: start 7, 3 bit, big-endian, init-value=0, base-type=uint8, compu {0..7=RANGE, 0=Cx0_LkaNoInterv, 1=Cx1_LkaIncrIntervLeft, 2=Cx2_LkaStandIntervLeft, 3=Cx3_LkaSupprLeft, 4=Cx4_LkaStandIntervRight, 5=Cx5_LkaSupprRight, 6=Cx6_LkaIncrIntervRight, 7=Cx7_NotUsed; unit SED}, unit=SED, transfer-property=PENDING, to PSCM_FD
          signal LaCurvature_No_Calc_oLane_Assist_Data1_FD1_oFD1_CAN: start 15, 12 bit, big-endian, init-value=2048, base-type=uint16, compu {4095=CxFFF_Fault, phys=raw*5e-06-0.01024 for raw 0..4095; unit 1/m} "Source signal range: [0,4094]", unit=1/m, transfer-property=PENDING, to PSCM_FD
          signal LaRefAng_No_Req_oLane_Assist_Data1_FD1_oFD1_CAN: start 19, 12 bit, big-endian, init-value=2048, base-type=uint16, compu {4095=CxFFF_Fault, phys=raw*0.05-102.4 for raw 0..4095; unit mrad} "Source signal range: [0,4094]", unit=mrad, transfer-property=PENDING, to PSCM_FD
          signal LkaDrvOvrrd_D_Rq_oLane_Assist_Data1_FD1_oFD1_CAN: start 38, 2 bit, big-endian, init-value=0, base-type=uint8, compu {0..3=RANGE, 0=Cx0_Level_0, 1=Cx1_Level_1, 2=Cx2_Level_2, 3=Cx3_Level_3; unit SED}, unit=SED, transfer-property=PENDING, to PSCM_FD
          signal LaRampType_B_Req_oLane_Assist_Data1_FD1_oFD1_CAN: start 39, 1 bit, big-endian, init-value=0, base-type=boolean, compu {0..1=RANGE, 0=Cx0_Smooth, 1=Cx1_Quick; unit SED}, unit=SED, transfer-property=PENDING, to PSCM_FD
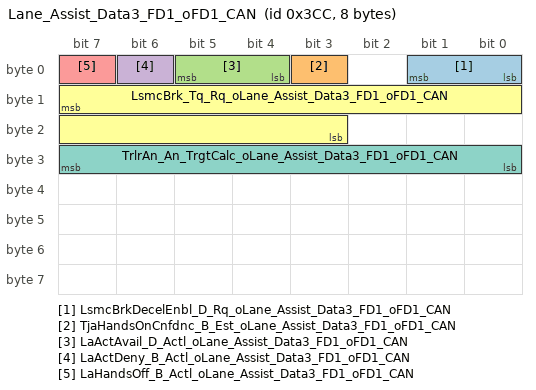
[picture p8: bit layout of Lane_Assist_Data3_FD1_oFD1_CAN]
      frame Lane_Assist_Data3_FD1_oFD1_CAN: id 0x3CC, from PSCM_FD, frame-length=8, variation-point=post-build-variant-condition{matching-criterion=Communication, value=0}, can-addressing-mode=STANDARD, can-frame-rx-behavior=ANY, can-frame-tx-behavior=CAN-FD
        pdu Lane_Assist_Data3_FD1_oFD1_CAN: length=8, minimum-delay=0.01, transmission-mode-false-timing=cyclic-timing={time-offset=0, time-period=0.03}, transmission-mode-true-timing=cyclic-timing={time-offset=0, time-period=0.03}, unused-bit-pattern=0
          signal LsmcBrkDecelEnbl_D_Rq_oLane_Assist_Data3_FD1_oFD1_CAN: start 1, 2 bit, big-endian, init-value=0, base-type=uint8, compu {0..3=RANGE, 0=Cx0_Off, 1=Cx1_On, 2=Cx2_NotUsed1, 3=Cx3_NotUsed2; unit SED}, unit=SED, transfer-property=PENDING
          signal TjaHandsOnCnfdnc_B_Est_oLane_Assist_Data3_FD1_oFD1_CAN: start 3, 1 bit, big-endian, init-value=1, base-type=boolean, compu {0..1=RANGE, 0=Cx0_Low_Confidence, 1=Cx1_High_Confidence; unit SED}, unit=SED, transfer-property=PENDING
          signal LaActAvail_D_Actl_oLane_Assist_Data3_FD1_oFD1_CAN: start 5, 2 bit, big-endian, init-value=0, base-type=uint8, compu {0..3=RANGE, 0=Cx0_LCA_LKA_LDW_Suppress, 1=Cx1_LCA_LKA_Suppress_LDW_Avail, 2=Cx2_LCA_LKA_Avail_LDW_Suppress, 3=Cx3_LKA_LCA_LDW_Avail; unit SED}, unit=SED, transfer-property=PENDING
          signal LaActDeny_B_Actl_oLane_Assist_Data3_FD1_oFD1_CAN: start 6, 1 bit, big-endian, init-value=0, base-type=boolean, compu {0..1=RANGE, 0=Cx0_LA_Not_Denied, 1=Cx1_LA_Denied; unit SED}, unit=SED, transfer-property=PENDING
          signal LaHandsOff_B_Actl_oLane_Assist_Data3_FD1_oFD1_CAN: start 7, 1 bit, big-endian, init-value=1, base-type=boolean, compu {0..1=RANGE, 0=Cx0_Hands_On, 1=Cx1_Hands_Off; unit SED}, unit=SED, transfer-property=PENDING
          signal LsmcBrk_Tq_Rq_oLane_Assist_Data3_FD1_oFD1_CAN: start 15, 13 bit, big-endian, init-value=0, base-type=uint16, compu {phys=raw*4 for raw 0..8191; unit Nm}, unit=Nm, transfer-property=PENDING
          signal TrlrAn_An_TrgtCalc_oLane_Assist_Data3_FD1_oFD1_CAN: start 31, 8 bit, big-endian, init-value=128, base-type=uint8, compu {phys=raw-128 for raw 0..255; unit degrees}, unit=degrees, transfer-property=PENDING
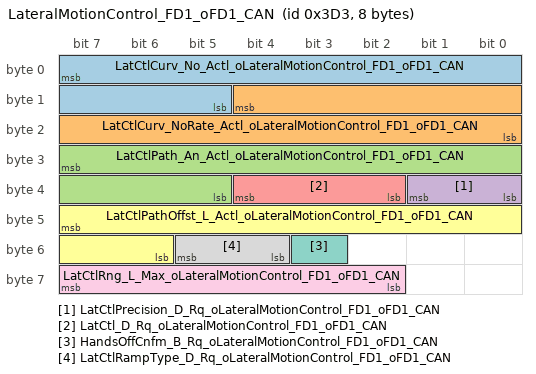
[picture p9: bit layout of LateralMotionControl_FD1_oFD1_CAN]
      frame LateralMotionControl_FD1_oFD1_CAN: id 0x3D3, to PSCM_FD, frame-length=8, can-addressing-mode=STANDARD, can-frame-rx-behavior=ANY, can-frame-tx-behavior=CAN-FD
        pdu LateralMotionControl_FD1_oFD1_CAN: length=8, minimum-delay=0.02, unused-bit-pattern=0
          signal LatCtlCurv_No_Actl_oLateralMotionControl_FD1_oFD1_CAN: start 7, 11 bit, big-endian, init-value=1000, base-type=uint16, compu {phys=raw*2e-05-0.02 for raw 0..2047; unit 1/meter}, unit=1/meter, transfer-property=PENDING, to PSCM_FD
          signal LatCtlCurv_NoRate_Actl_oLateralMotionControl_FD1_oFD1_CAN: start 12, 13 bit, big-endian, init-value=4096, base-type=uint16, compu {phys=raw/4000000-0.001024 for raw 0..8191; unit 1/meter}, unit=1/meter, transfer-property=PENDING, to PSCM_FD
          signal LatCtlPath_An_Actl_oLateralMotionControl_FD1_oFD1_CAN: start 31, 11 bit, big-endian, init-value=1000, base-type=uint16, compu {phys=raw*0.0005-0.5 for raw 0..2046; unit radians}, unit=radians, transfer-property=PENDING, to PSCM_FD
          signal LatCtlPrecision_D_Rq_oLateralMotionControl_FD1_oFD1_CAN: start 33, 2 bit, big-endian, init-value=0, base-type=uint8, compu {0..3=RANGE, 0=Cx0_Comfortable, 1=Cx1_Precise, 2=Cx2_NotUsed1, 3=Cx3_NotUsed2; unit SED}, unit=SED, transfer-property=PENDING, to PSCM_FD
          signal LatCtl_D_Rq_oLateralMotionControl_FD1_oFD1_CAN: start 36, 3 bit, big-endian, init-value=0, base-type=uint8, compu {0..7=RANGE, 0=Cx0_NoLateralControl, 1=Cx1_ContinuousPathFollowing, 2=Cx2_InterventionLeft, 3=Cx3_InterventionRight, 4=Cx4_NotUsed1, 5=Cx5_NotUsed2, 6=Cx6_NotUsed3, 7=Cx7_NotUsed4; unit SED}, unit=SED, transfer-property=PENDING, to PSCM_FD
          signal LatCtlPathOffst_L_Actl_oLateralMotionControl_FD1_oFD1_CAN: start 47, 10 bit, big-endian, init-value=512, base-type=uint16, compu {phys=raw*0.01-5.12 for raw 0..1023; unit meter}, unit=meter, transfer-property=PENDING, to PSCM_FD
          signal HandsOffCnfm_B_Rq_oLateralMotionControl_FD1_oFD1_CAN: start 51, 1 bit, big-endian, init-value=0, base-type=boolean, compu {0..1=RANGE, 0=Cx0_Inactive, 1=Cx1_Active; unit SED}, unit=SED, transfer-property=PENDING, to PSCM_FD
          signal LatCtlRampType_D_Rq_oLateralMotionControl_FD1_oFD1_CAN: start 53, 2 bit, big-endian, init-value=0, base-type=uint8, compu {0..3=RANGE, 0=Cx0_Slow, 1=Cx1_Medium, 2=Cx2_Fast, 3=Cx3_Immediately; unit SED}, unit=SED, transfer-property=PENDING, to PSCM_FD
          signal LatCtlRng_L_Max_oLateralMotionControl_FD1_oFD1_CAN: start 63, 6 bit, big-endian, init-value=0, base-type=uint8, compu {phys=raw*2 for raw 0..63; unit meter}, unit=meter, transfer-property=PENDING, to PSCM_FD
      frame Mc_Send_Signals_2_FD1_oFD1_CAN: id 0x2FD, to PSCM_FD, frame-length=8, can-addressing-mode=STANDARD, can-frame-rx-behavior=ANY, can-frame-tx-behavior=CAN-FD
        pdu Mc_Send_Signals_2_FD1_oFD1_CAN: length=8, minimum-delay=0.02, unused-bit-pattern=0
          signal EsaOn_B_Rq_oMc_Send_Signals_2_FD1_oFD1_CAN: start 15, 1 bit, big-endian, init-value=1, base-type=boolean, compu {0..1=RANGE, 0=Cx0_Off, 1=Cx1_On; unit SED}, unit=SED, transfer-property=PENDING, to PSCM_FD
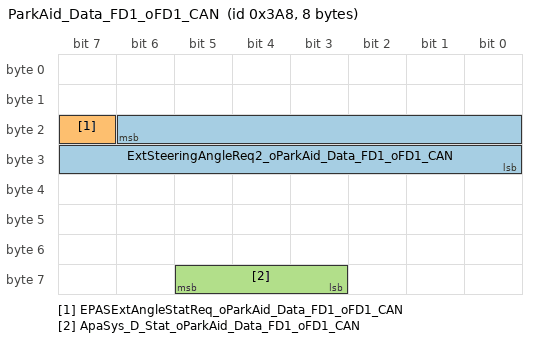
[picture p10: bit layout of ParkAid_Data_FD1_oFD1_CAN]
      frame ParkAid_Data_FD1_oFD1_CAN: id 0x3A8, to PSCM_FD, frame-length=8, can-addressing-mode=STANDARD, can-frame-rx-behavior=ANY, can-frame-tx-behavior=CAN-FD
        pdu ParkAid_Data_FD1_oFD1_CAN: length=8, minimum-delay=0.01, transmission-mode-false-timing=cyclic-timing={time-offset=0, time-period=0.02}, transmission-mode-true-timing=cyclic-timing={time-offset=0, time-period=0.02}, unused-bit-pattern=0
          signal ExtSteeringAngleReq2_oParkAid_Data_FD1_oFD1_CAN: start 22, 15 bit, big-endian, init-value=0, base-type=uint16, compu {32766=Cx7FFE_Unknown, 32767=Cx7FFF_Invalid, phys=raw*0.1-1000 for raw 0..32767; unit Degrees} "Source signal range: [0,32765]", unit=Degrees, transfer-property=PENDING, to PSCM_FD
          signal EPASExtAngleStatReq_oParkAid_Data_FD1_oFD1_CAN: start 23, 1 bit, big-endian, init-value=0, base-type=boolean, compu {0..1=RANGE, 0=Cx0_NoRequest, 1=Cx1_Request; unit SED}, unit=SED, transfer-property=PENDING, to PSCM_FD
          signal ApaSys_D_Stat_oParkAid_Data_FD1_oFD1_CAN: start 61, 3 bit, big-endian, init-value=0, base-type=uint8, compu {0..7=RANGE, 0=Cx0_Null, 1=Cx1_Off, 2=Cx2_On, 3=Cx3_Overspeed, 4=Cx4_ApaCancelled, 5=Cx5_NotAccessible, 6=Cx6_Finished, 7=Cx7_Faulty; unit SED}, unit=SED, transfer-property=PENDING, to PSCM_FD
      frame PowertrainData_10_FD1_oFD1_CAN: id 0x176, to PSCM_FD, frame-length=8, can-addressing-mode=STANDARD, can-frame-rx-behavior=ANY, can-frame-tx-behavior=CAN-FD  # Programs w/o HS1 0x172 will need HS1 0x176 for GearPos_D_Actl. Future MY Programs that choose c/o still require HS1 0x172.
        pdu PowertrainData_10_FD1_oFD1_CAN: length=8, minimum-delay=0.02, transmission-mode-false-timing={cyclic-timing={time-offset=0, time-period=0.1}, event-controlled-timing={number-of-repetitions=0, repetition-period=0}}, transmission-mode-true-timing={cyclic-timing={time-offset=0, time-period=0.1}, event-controlled-timing={number-of-repetitions=0, repetition-period=0}}, unused-bit-pattern=0
          signal GearPos_D_Actl_oPowertrainData_10_FD1_oFD1_CAN: start 3, 4 bit, big-endian, init-value=15, base-type=uint8, compu {0..15=RANGE, 0=Cx0_Neutral, 1=Cx1_First, 2=Cx2_Second, 3=Cx3_Third, 4=Cx4_Fourth, 5=Cx5_Fifth, 6=Cx6_Sixth, 7=Cx7_Seventh, 8=Cx8_Eighth, 9=Cx9_Ninth, 10=CxA_Tenth, 11=CxB_Undefined_3, 12=CxC_Undefined_4, 13=CxD_Undefined_5, 14=CxE_Reverse, 15=CxF_Unknown; unit SED}, unit=SED, transfer-property=TRIGGERED-ON-CHANGE-WITHOUT-REPETITION, to PSCM_FD  # Powersplit HEVs with HF45, HPCM will Tx this message. For all other programs it will be Tx by PCM or TCM.
          signal TrnRng_D_Rq_oPowertrainData_10_FD1_oFD1_CAN: start 27, 4 bit, big-endian, init-value=14, base-type=uint8, compu {0..15=RANGE, 0=Cx0_Park, 1=Cx1_Reverse, 2=Cx2_Neutral, 3=Cx3_Drive, 4=Cx4_Sport_DriveSport_Mposition, 5=Cx5_Low, 6=Cx6_Range1_M1_L1, 7=Cx7_Range2_M2_L2, 8=Cx8_Range3_M3_L3, 9=Cx9_Range4, 10=CxA_Range5, 11=CxB_Range6, 12=CxC_NotUsed_1, 13=CxD_NotUsed_2, 14=CxE_Unknown_Position, 15=CxF_Fault; unit SED}, unit=SED, transfer-property=TRIGGERED-ON-CHANGE-WITHOUT-REPETITION, to PSCM_FD  # Powersplit HEVs with HF45, HPCM will Tx this message. For all other programs it will be Tx by PCM or TCM.
      frame PSCM_AutoSar_NetwrkMgt_FD1_oFD1_CAN: id 0x5B5, from PSCM_FD, frame-length=8, variation-point=post-build-variant-condition{matching-criterion=Communication, value=0}, can-addressing-mode=STANDARD, can-frame-rx-behavior=ANY, can-frame-tx-behavior=CAN-FD
        nm pdu PSCM_AutoSar_NetwrkMgt_FD1_oFD1_CAN: length=8, unused-bit-pattern=0
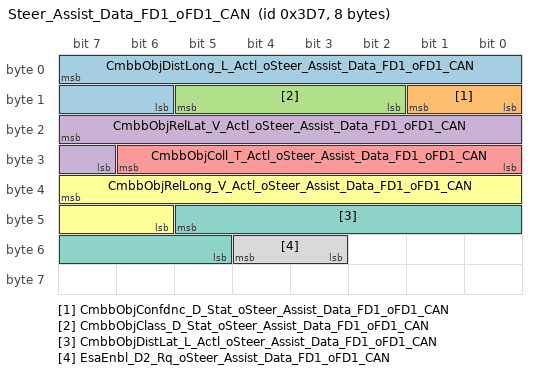
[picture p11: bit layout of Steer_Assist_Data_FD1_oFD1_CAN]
      frame Steer_Assist_Data_FD1_oFD1_CAN: id 0x3D7, to PSCM_FD, frame-length=8, can-addressing-mode=STANDARD, can-frame-rx-behavior=ANY, can-frame-tx-behavior=CAN-FD
        pdu Steer_Assist_Data_FD1_oFD1_CAN: length=8, minimum-delay=0.02, unused-bit-pattern=0
          signal CmbbObjDistLong_L_Actl_oSteer_Assist_Data_FD1_oFD1_CAN: start 7, 10 bit, big-endian, init-value=1022, base-type=uint16, compu {1022=Cx3FE_NoDataExists, 1023=Cx3FF_Faulty, phys=raw*0.1 for raw 0..1023; unit meter} "Source signal range: [0,1021]", unit=meter, transfer-property=PENDING, to PSCM_FD
          signal CmbbObjConfdnc_D_Stat_oSteer_Assist_Data_FD1_oFD1_CAN: start 9, 2 bit, big-endian, init-value=0, base-type=uint8, compu {0..3=RANGE, 0=Cx0_NotDetermined, 1=Cx1_Low, 2=Cx2_Medium, 3=Cx3_High; unit SED}, unit=SED, transfer-property=PENDING, to PSCM_FD
          signal CmbbObjClass_D_Stat_oSteer_Assist_Data_FD1_oFD1_CAN: start 13, 4 bit, big-endian, init-value=0, base-type=uint8, compu {0..15=RANGE, 0=Cx0_Undetermined, 1=Cx1_Vehicle, 2=Cx2_Motorcycle, 3=Cx3_Truck, 4=Cx4_Pedestrian, 5=Cx5_Bicycle, 6=Cx6_Unclassified_Vehicle, 7=Cx7_NotUsed_1, 8=Cx8_NotUsed_2, 9=Cx9_NotUsed_3, 10=CxA_NotUsed_4, 11=CxB_NotUsed_5, 12=CxC_NotUsed_6, 13=CxD_NotUsed_7, 14=CxE_NotUsed_8, 15=CxF_NotUsed_9; unit SED}, unit=SED, transfer-property=PENDING, to PSCM_FD
          signal CmbbObjRelLat_V_Actl_oSteer_Assist_Data_FD1_oFD1_CAN: start 23, 9 bit, big-endian, init-value=510, base-type=uint16, compu {510=Cx1FE_NoDataExists, 511=Cx1FF_Faulty, phys=raw*0.1-25.5 for raw 0..511; unit meters/sec} "Source signal range: [0,509]", unit=meters/sec, transfer-property=PENDING, to PSCM_FD
          signal CmbbObjColl_T_Actl_oSteer_Assist_Data_FD1_oFD1_CAN: start 30, 7 bit, big-endian, init-value=126, base-type=uint8, compu {126=Cx7E_NoDataExists, 127=Cx7F_Faulty, phys=raw*0.05 for raw 0..127; unit second} "Source signal range: [0,125]", unit=second, transfer-property=PENDING, to PSCM_FD
          signal CmbbObjRelLong_V_Actl_oSteer_Assist_Data_FD1_oFD1_CAN: start 39, 10 bit, big-endian, init-value=1022, base-type=uint16, compu {1022=Cx3FE_NoDataExists, 1023=Cx3FF_Faulty, phys=raw*0.1-102.1 for raw 0..1023; unit meters/sec} "Source signal range: [0,1021]", unit=meters/sec, transfer-property=PENDING, to PSCM_FD
          signal CmbbObjDistLat_L_Actl_oSteer_Assist_Data_FD1_oFD1_CAN: start 45, 9 bit, big-endian, init-value=510, base-type=uint16, compu {510=Cx1FE_NoDataExists, 511=Cx1FF_Faulty, phys=raw*0.1-25.5 for raw 0..511; unit meter} "Source signal range: [0,509]", unit=meter, transfer-property=PENDING, to PSCM_FD
          signal EsaEnbl_D2_Rq_oSteer_Assist_Data_FD1_oFD1_CAN: start 52, 2 bit, big-endian, init-value=0, base-type=uint8, compu {0..3=RANGE, 0=Cx0_Disabled, 1=Cx1_Pending, 2=Cx2_Enabled, 3=Cx3_NotConfigured; unit SED}, unit=SED, transfer-property=PENDING, to PSCM_FD
      frame Steering_Data_FD1_oFD1_CAN: id 0x83, to PSCM_FD, frame-length=8, can-addressing-mode=STANDARD, can-frame-rx-behavior=ANY, can-frame-tx-behavior=CAN-FD
        pdu Steering_Data_FD1_oFD1_CAN: length=8, minimum-delay=0.02, unused-bit-pattern=0
          signal TurnLghtSwtch_D_Stat_oSteering_Data_FD1_oFD1_CAN: start 5, 2 bit, big-endian, init-value=0, base-type=uint8, compu {0..3=RANGE, 0=Cx0_Off, 1=Cx1_Left, 2=Cx2_Right, 3=Cx3_Unused_Treat_As_Off; unit SED}, unit=SED, transfer-property=PENDING, to PSCM_FD
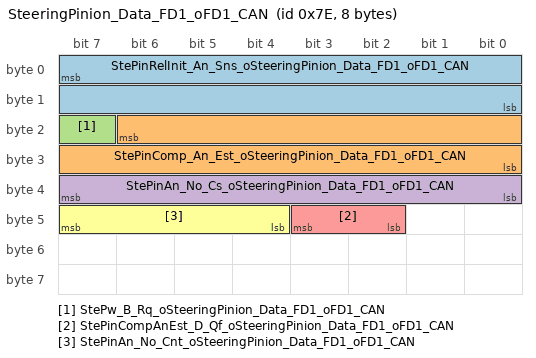
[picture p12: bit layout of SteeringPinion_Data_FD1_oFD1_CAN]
      frame SteeringPinion_Data_FD1_oFD1_CAN: id 0x7E, from PSCM_FD, frame-length=8, variation-point=post-build-variant-condition{matching-criterion=Communication, value=0}, can-addressing-mode=STANDARD, can-frame-rx-behavior=ANY, can-frame-tx-behavior=CAN-FD
        pdu SteeringPinion_Data_FD1_oFD1_CAN: length=8, minimum-delay=0, transmission-mode-false-timing=cyclic-timing={time-offset=0, time-period=0.01}, transmission-mode-true-timing=cyclic-timing={time-offset=0, time-period=0.01}, unused-bit-pattern=0
          signal StePinRelInit_An_Sns_oSteeringPinion_Data_FD1_oFD1_CAN: start 7, 16 bit, big-endian, init-value=65535, base-type=uint16, compu {65534=CxFFFE_NoDataExists, 65535=CxFFFF_Faulty, phys=raw*0.1-3200 for raw 0..65535; unit degrees} "Source signal range: [0,65533]", unit=degrees, transfer-property=PENDING  # SASM will transmit these signals on vehicles with SASM and without PSCM. SCCM will not Tx this signal when SASM is present.
          signal StePinComp_An_Est_oSteeringPinion_Data_FD1_oFD1_CAN: start 22, 15 bit, big-endian, init-value=16000, base-type=uint16, compu {phys=raw*0.1-1600 for raw 0..32766; unit degrees}, unit=degrees, transfer-property=PENDING
          signal StePw_B_Rq_oSteeringPinion_Data_FD1_oFD1_CAN: start 23, 1 bit, big-endian, init-value=0, base-type=boolean, compu {0..1=RANGE, 0=Cx0_No, 1=Cx1_Yes; unit SED}, unit=SED, transfer-property=PENDING
          signal StePinAn_No_Cs_oSteeringPinion_Data_FD1_oFD1_CAN: start 39, 8 bit, big-endian, init-value=0, base-type=uint8, compu {0..255=RANGE; unit Unitless}, unit=Unitless, transfer-property=PENDING  # Signal not transmitted on gas variants.
          signal StePinCompAnEst_D_Qf_oSteeringPinion_Data_FD1_oFD1_CAN: start 43, 2 bit, big-endian, init-value=1, base-type=uint8, compu {0..3=RANGE, 0=Cx0_Faulty, 1=Cx1_No_Data_Exists, 2=Cx2_Degraded, 3=Cx3_OK; unit SED}, unit=SED, transfer-property=PENDING
          signal StePinAn_No_Cnt_oSteeringPinion_Data_FD1_oFD1_CAN: start 47, 4 bit, big-endian, init-value=0, base-type=uint8, compu {0..15=RANGE; unit unitless}, unit=unitless, transfer-property=PENDING
      frame TesterFunctionalReq_FD1_oFD1_CAN: id 0x7DF, to PSCM_FD, frame-length=64, variation-point=post-build-variant-condition{matching-criterion=Communication, value=0}, can-addressing-mode=STANDARD, can-frame-rx-behavior=CAN-FD, can-frame-tx-behavior=CAN-FD  # OBDII Request ($7DF) messages are for FNOS 1.0.1 only. Diagnostic Functional Addressing ($7DF) and Dual Rate Periodic messages are for FNOS I3 only.
        n pdu TesterFunctionalReq_FD1_Tp_oFD1_CAN: length=64
      frame TesterFunctionalReq_FD1_oFD1_CAN_20: id 0x7DF, to PSCM_FD, frame-length=8, variation-point=post-build-variant-condition{matching-criterion=Communication, value=0}, can-addressing-mode=STANDARD, can-frame-rx-behavior=CAN-20, can-frame-tx-behavior=CAN-20
        n pdu TesterFunctionalReq_FD1_Tp_oFD1_CAN_20: length=8
      frame TesterPhysicalReqPSCM_FD1_oFD1_CAN: id 0x730, to PSCM_FD, frame-length=64, variation-point=post-build-variant-condition{matching-criterion=Communication, value=0}, can-addressing-mode=STANDARD, can-frame-rx-behavior=CAN-FD, can-frame-tx-behavior=CAN-FD
        n pdu TesterPhysicalReqPSCM_FD1_Tp_oFD1_CAN: length=64
      frame TesterPhysicalReqPSCM_FD1_oFD1_CAN_20: id 0x730, to PSCM_FD, frame-length=8, variation-point=post-build-variant-condition{matching-criterion=Communication, value=0}, can-addressing-mode=STANDARD, can-frame-rx-behavior=CAN-20, can-frame-tx-behavior=CAN-20
        n pdu TesterPhysicalReqPSCM_FD1_Tp_oFD1_CAN_20: length=8
      frame TesterPhysicalResPSCM_FD1_oFD1_CAN: id 0x738, from PSCM_FD, frame-length=64, variation-point=post-build-variant-condition{matching-criterion=Communication, value=0}, can-addressing-mode=STANDARD, can-frame-rx-behavior=CAN-FD, can-frame-tx-behavior=CAN-FD
        n pdu TesterPhysicalResPSCM_FD1_Tp_oFD1_CAN: length=64
      frame TesterPhysicalResPSCM_FD1_oFD1_CAN_20: id 0x738, from PSCM_FD, frame-length=8, variation-point=post-build-variant-condition{matching-criterion=Communication, value=0}, can-addressing-mode=STANDARD, can-frame-rx-behavior=CAN-20, can-frame-tx-behavior=CAN-20
        n pdu TesterPhysicalResPSCM_FD1_Tp_oFD1_CAN_20: length=8
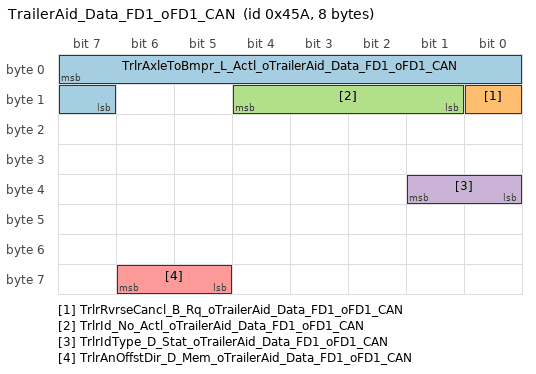
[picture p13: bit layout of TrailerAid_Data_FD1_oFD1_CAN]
      frame TrailerAid_Data_FD1_oFD1_CAN: id 0x45A, to PSCM_FD, frame-length=8, can-addressing-mode=STANDARD, can-frame-rx-behavior=ANY, can-frame-tx-behavior=CAN-FD
        pdu TrailerAid_Data_FD1_oFD1_CAN: length=8, minimum-delay=0.02, unused-bit-pattern=0
          signal TrlrAxleToBmpr_L_Actl_oTrailerAid_Data_FD1_oFD1_CAN: start 7, 9 bit, big-endian, init-value=0, base-type=uint16, compu {phys=raw*0.0254 for raw 0..511; unit meter}, unit=meter, transfer-property=PENDING, to PSCM_FD
          signal TrlrRvrseCancl_B_Rq_oTrailerAid_Data_FD1_oFD1_CAN: start 8, 1 bit, big-endian, init-value=0, base-type=boolean, compu {0..1=RANGE, 0=Cx0_Null, 1=Cx1_Cancel; unit SED}, unit=SED, transfer-property=PENDING, to PSCM_FD
          signal TrlrId_No_Actl_oTrailerAid_Data_FD1_oFD1_CAN: start 12, 4 bit, big-endian, init-value=0, base-type=uint8, compu {0..15=RANGE; unit unitless}, unit=unitless, transfer-property=PENDING, to PSCM_FD
          signal TrlrIdType_D_Stat_oTrailerAid_Data_FD1_oFD1_CAN: start 33, 2 bit, big-endian, init-value=0, base-type=uint8, compu {0..3=RANGE, 0=Cx0_Null, 1=Cx1_Conventional, 2=Cx2_FifthWheel, 3=Cx3_Gooseneck; unit SED}, unit=SED, transfer-property=PENDING, to PSCM_FD
          signal TrlrAnOffstDir_D_Mem_oTrailerAid_Data_FD1_oFD1_CAN: start 62, 2 bit, big-endian, init-value=0, base-type=uint8, compu {0..3=RANGE, 0=Cx0_Null, 1=Cx1_Left_or_Center, 2=Cx2_Right, 3=Cx3_NotUSed; unit SED}, unit=SED, transfer-property=PENDING, to PSCM_FD
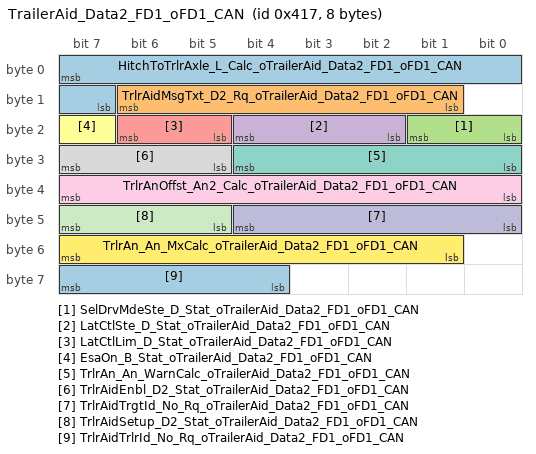
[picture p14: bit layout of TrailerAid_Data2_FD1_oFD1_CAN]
      frame TrailerAid_Data2_FD1_oFD1_CAN: id 0x417, from PSCM_FD, frame-length=8, variation-point=post-build-variant-condition{matching-criterion=Communication, value=0}, can-addressing-mode=STANDARD, can-frame-rx-behavior=ANY, can-frame-tx-behavior=CAN-FD
        pdu TrailerAid_Data2_FD1_oFD1_CAN: length=8, minimum-delay=0.02, transmission-mode-false-timing={cyclic-timing={time-offset=0, time-period=1}, event-controlled-timing={number-of-repetitions=0, repetition-period=0}}, transmission-mode-true-timing={cyclic-timing={time-offset=0, time-period=1}, event-controlled-timing={number-of-repetitions=0, repetition-period=0}}, unused-bit-pattern=0
          signal HitchToTrlrAxle_L_Calc_oTrailerAid_Data2_FD1_oFD1_CAN: start 7, 9 bit, big-endian, init-value=0, base-type=uint16, compu {phys=raw*0.0254 for raw 0..511; unit meter}, unit=meter, transfer-property=PENDING
          signal TrlrAidMsgTxt_D2_Rq_oTrailerAid_Data2_FD1_oFD1_CAN: start 14, 6 bit, big-endian, init-value=0, base-type=uint8, compu {0..63=RANGE, 0=Cx00_NoMessage, 1=Cx01_Message1, 2=Cx02_Message2, 3=Cx03_Message3, 4=Cx04_Message4, 5=Cx05_Message5, 6=Cx06_Message6, 7=Cx07_Message7, 8=Cx08_Message8, 9=Cx09_Message9, 10=Cx0A_Message10, 11=Cx0B_Message11, 12=Cx0C_Message12, 13=Cx0D_Message13, 14=Cx0E_Message14, 15=Cx0F_Message15, 16=Cx10_Message16, 17=Cx11_Message17, 18=Cx12_Message18, 19=Cx13_Message19, 20=Cx14_Message20, 21=Cx15_Message21, 22=Cx16_Message22, 23=Cx17_Message23, 24=Cx18_Message24, 25=Cx19_Message25, 26=Cx1A_Message26, 27=Cx1B_Message27, 28=Cx1C_Message28, 29=Cx1D_Message29, 30=Cx1E_Message30, 31=Cx1F_Message31, 35=Cx23_Message35, 40=Cx28_Message40, 45=Cx2D_Message45, 50=Cx32_Message50, 55=Cx37_Message55, 60=Cx3C_Message60, 61=Cx3D_Message61, 62=Cx3E_Message62, 63=Cx3F_Message63; unit SED}, unit=SED, transfer-property=TRIGGERED-ON-CHANGE-WITHOUT-REPETITION
          signal SelDrvMdeSte_D_Stat_oTrailerAid_Data2_FD1_oFD1_CAN: start 17, 2 bit, big-endian, init-value=0, base-type=uint8, compu {0..3=RANGE, 0=Cx0_NotAvailable, 1=Cx1_Available, 2=Cx2_TemporarilyNotAvailable, 3=Cx3_Faulty; unit SED}, unit=SED, transfer-property=TRIGGERED-ON-CHANGE-WITHOUT-REPETITION
          signal LatCtlSte_D_Stat_oTrailerAid_Data2_FD1_oFD1_CAN: start 20, 3 bit, big-endian, init-value=0, base-type=uint8, compu {0..7=RANGE, 0=Cx0_Unavailable, 1=Cx1_Available, 2=Cx2_ContLatControlInProgress, 3=Cx3_RampOut, 4=Cx4_Denied, 5=Cx5_NotUsed1, 6=Cx6_NotUsed2, 7=Cx7_NotUsed3; unit SED}, unit=SED, transfer-property=TRIGGERED-ON-CHANGE-WITHOUT-REPETITION
          signal LatCtlLim_D_Stat_oTrailerAid_Data2_FD1_oFD1_CAN: start 22, 2 bit, big-endian, init-value=0, base-type=uint8, compu {0..3=RANGE, 0=Cx0_LimitNotReached, 1=Cx1_LimitClose, 2=Cx2_LimitReached, 3=Cx3_LimitWithDriverActive; unit SED}, unit=SED, transfer-property=TRIGGERED-ON-CHANGE-WITHOUT-REPETITION
          signal EsaOn_B_Stat_oTrailerAid_Data2_FD1_oFD1_CAN: start 23, 1 bit, big-endian, init-value=1, base-type=boolean, compu {0..1=RANGE, 0=Cx0_Off, 1=Cx1_On; unit SED}, unit=SED, transfer-property=TRIGGERED-ON-CHANGE-WITHOUT-REPETITION
          signal TrlrAn_An_WarnCalc_oTrailerAid_Data2_FD1_oFD1_CAN: start 28, 5 bit, big-endian, init-value=0, base-type=uint8, compu {0..31=RANGE; unit degrees}, unit=degrees, transfer-property=PENDING
          signal TrlrAidEnbl_D2_Stat_oTrailerAid_Data2_FD1_oFD1_CAN: start 31, 3 bit, big-endian, init-value=0, base-type=uint8, compu {0..7=RANGE, 0=Cx0_Inactive, 1=Cx1_TbaActive, 2=Cx2_TbaSetup, 3=Cx3_TbaOffTrgSetup, 4=Cx4_TbaOffTrgActive, 5=Cx5_TbaActiveExpertAvail, 6=Cx6_TbaActiveExpertActive, 7=Cx7_NotUsed_1; unit SED}, unit=SED, transfer-property=TRIGGERED-ON-CHANGE-WITHOUT-REPETITION
          signal TrlrAnOffst_An2_Calc_oTrailerAid_Data2_FD1_oFD1_CAN: start 39, 8 bit, big-endian, init-value=128, base-type=uint8, compu {phys=raw*0.5-64 for raw 0..255; unit degrees}, unit=degrees, transfer-property=PENDING
          signal TrlrAidTrgtId_No_Rq_oTrailerAid_Data2_FD1_oFD1_CAN: start 44, 5 bit, big-endian, init-value=0, base-type=uint8, compu {0..31=RANGE; unit unitless}, unit=unitless, transfer-property=PENDING
          signal TrlrAidSetup_D2_Stat_oTrailerAid_Data2_FD1_oFD1_CAN: start 47, 3 bit, big-endian, init-value=0, base-type=uint8, compu {0..7=RANGE, 0=Cx0_Null, 1=Cx1_TbaActive, 2=Cx2_SetupPrepForAcquisition, 3=Cx3_SetupStartAcquisition, 4=Cx4_TbaTadMonitor, 5=Cx5_SetupAcquisitionSuccess, 6=Cx6_NotUsed_1, 7=Cx7_NotUsed_2; unit SED}, unit=SED, transfer-property=PENDING
          signal TrlrAn_An_MxCalc_oTrailerAid_Data2_FD1_oFD1_CAN: start 55, 7 bit, big-endian, init-value=0, base-type=uint8, compu {0..127=RANGE; unit degrees}, unit=degrees, transfer-property=PENDING
          signal TrlrAidTrlrId_No_Rq_oTrailerAid_Data2_FD1_oFD1_CAN: start 63, 4 bit, big-endian, init-value=0, base-type=uint8, compu {0..15=RANGE; unit unitless}, unit=unitless, transfer-property=PENDING
      frame TrailerAid_Data3_FD1_oFD1_CAN: id 0x45C, to PSCM_FD, frame-length=8, can-addressing-mode=STANDARD, can-frame-rx-behavior=ANY, can-frame-tx-behavior=CAN-FD
        pdu TrailerAid_Data3_FD1_oFD1_CAN: length=8, minimum-delay=0.02, unused-bit-pattern=0
          signal TrlrAidSetup_D2_Rq_oTrailerAid_Data3_FD1_oFD1_CAN: start 4, 4 bit, big-endian, init-value=0, base-type=uint8, compu {0..15=RANGE, 0=Cx0_Inactive, 1=Cx1_BeginSetup, 2=Cx2_EndSetup, 3=Cx3_ConfirmSetup, 4=Cx4_StickerNotCircled, 5=Cx5_ReturnToSetup, 6=Cx6_CompleteSetup, 7=Cx7_NotUsed_1, 8=Cx8_NotUsed_2, 9=Cx9_NotUsed_3, 10=CxA_NotUsed_4, 11=CxB_NotUsed_5, 12=CxC_NotUsed_6, 13=CxD_NotUsed_7, 14=CxE_NotUsed_8, 15=CxF_NotUsed_9; unit SED}, unit=SED, transfer-property=PENDING, to PSCM_FD
          signal TrlrAidEnbl_D2_Rq_oTrailerAid_Data3_FD1_oFD1_CAN: start 7, 3 bit, big-endian, init-value=0, base-type=uint8, compu {0..7=RANGE, 0=Cx0_Inactive, 1=Cx1_ActivateTba, 2=Cx2_ActivateTrg, 3=Cx3_Deactivate, 4=Cx4_NotUsed_1, 5=Cx5_NotUsed_2, 6=Cx6_NotUsed_3, 7=Cx7_NotUsed_4; unit SED}, unit=SED, transfer-property=PENDING, to PSCM_FD
      frame TrailerAid_Stat1_FD1_oFD1_CAN: id 0x452, to PSCM_FD, frame-length=8, can-addressing-mode=STANDARD, can-frame-rx-behavior=ANY, can-frame-tx-behavior=CAN-FD  # new RCM Serial Trailer Aid (TrailerAid_Stat1) 48 bits
        pdu TrailerAid_Stat1_FD1_oFD1_CAN: length=8, minimum-delay=0.02, unused-bit-pattern=0
          signal TrlrSnsId_No_Actl_oTrailerAid_Stat1_FD1_oFD1_CAN: start 0, 48 bit, opaque, init-value=6 x 0, base-type=uint8_6_iso_8859_1, compu {0..281474976710650=RANGE, 4294967294=Cx0000FFFFFFFE_NoDataExists_FFFFFFFFFFFE, 4294967295=Cx0000FFFFFFFF_Faulty_FFFFFFFFFFFF; unit unitless}, unit=unitless, transfer-property=PENDING, to PSCM_FD
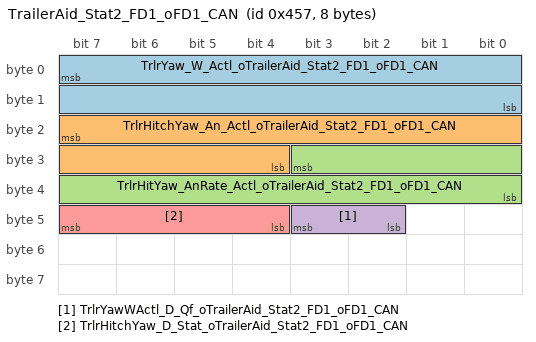
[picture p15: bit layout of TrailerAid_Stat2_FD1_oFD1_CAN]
      frame TrailerAid_Stat2_FD1_oFD1_CAN: id 0x457, to PSCM_FD, frame-length=8, can-addressing-mode=STANDARD, can-frame-rx-behavior=ANY, can-frame-tx-behavior=CAN-FD  # new RCM Serial Trailer Aid (TrailerAid_Stat1) 48 bits
        pdu TrailerAid_Stat2_FD1_oFD1_CAN: length=8, minimum-delay=0.02, unused-bit-pattern=0
          signal TrlrYaw_W_Actl_oTrailerAid_Stat2_FD1_oFD1_CAN: start 7, 16 bit, big-endian, init-value=65534, base-type=uint16, compu {65534=CxFFFE_NoDataExists, 65535=CxFFFF_Faulty, phys=raw*0.0002-6.5 for raw 0..65535; unit radians/second} "Source signal range: [0,65533]", unit=radians/second, transfer-property=PENDING, to PSCM_FD
          signal TrlrHitchYaw_An_Actl_oTrailerAid_Stat2_FD1_oFD1_CAN: start 23, 12 bit, big-endian, init-value=4094, base-type=uint16, compu {4094=CxFFE_NoDataExists, 4095=CxFFF_Faulty, phys=raw*0.1-90 for raw 0..4095; unit degrees} "Source signal range: [0,4093]", unit=degrees, transfer-property=PENDING, to PSCM_FD
          signal TrlrHitYaw_AnRate_Actl_oTrailerAid_Stat2_FD1_oFD1_CAN: start 27, 12 bit, big-endian, init-value=4094, base-type=uint16, compu {4094=CxFFE_NoDataExists, 4095=CxFFF_Fault, phys=raw*0.1-50 for raw 0..4095; unit degrees/second} "Source signal range: [0,4093]", unit=degrees/second, transfer-property=PENDING, to PSCM_FD
          signal TrlrYawWActl_D_Qf_oTrailerAid_Stat2_FD1_oFD1_CAN: start 43, 2 bit, big-endian, init-value=1, base-type=uint8, compu {0..3=RANGE, 0=Cx0_Faulty, 1=Cx1_No_Data_Exists, 2=Cx2_Not_Within_Specifications, 3=Cx3_OK; unit SED}, unit=SED, transfer-property=PENDING, to PSCM_FD
          signal TrlrHitchYaw_D_Stat_oTrailerAid_Stat2_FD1_oFD1_CAN: start 47, 4 bit, big-endian, init-value=0, base-type=uint8, compu {0..15=RANGE, 0=Cx0_NoConnectionWithYrsu, 1=Cx1_TadNotWithinSpecification, 2=Cx2_TadTrlrDataOutOfRange, 3=Cx3_InitInputs, 4=Cx4_InitNoTadAngle, 5=Cx5_LowConfdAngleMem, 6=Cx6_HiConfdAngleMem, 7=Cx7_LowConfdLrndAngle, 8=Cx8_HiConfdLrndAngle, 9=Cx9_FaultyYrsu, 10=CxA_FaultyYrsuConnection, 11=CxB_NotUsed_1, 12=CxC_NotUsed_2, 13=CxD_NotUsed_3, 14=CxE_NotUsed_4, 15=CxF_Faulty; unit SED}, unit=SED, transfer-property=PENDING, to PSCM_FD
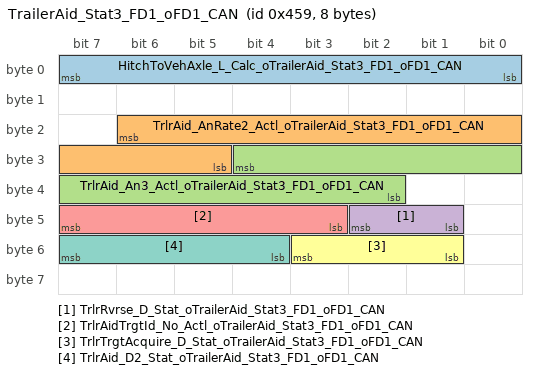
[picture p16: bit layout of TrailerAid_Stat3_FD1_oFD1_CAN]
      frame TrailerAid_Stat3_FD1_oFD1_CAN: id 0x459, to PSCM_FD, frame-length=8, can-addressing-mode=STANDARD, can-frame-rx-behavior=ANY, can-frame-tx-behavior=CAN-FD
        pdu TrailerAid_Stat3_FD1_oFD1_CAN: length=8, minimum-delay=0.02, transmission-mode-false-timing=cyclic-timing={time-offset=0, time-period=0.05}, transmission-mode-true-timing=cyclic-timing={time-offset=0, time-period=0.05}, unused-bit-pattern=0
          signal HitchToVehAxle_L_Calc_oTrailerAid_Stat3_FD1_oFD1_CAN: start 7, 8 bit, big-endian, init-value=255, base-type=uint8, compu {255=CxFF_Faulty, phys=raw*0.0127-0.508 for raw 0..255; unit meter} "Source signal range: [0,254]", unit=meter, transfer-property=PENDING, to PSCM_FD
          signal TrlrAid_AnRate2_Actl_oTrailerAid_Stat3_FD1_oFD1_CAN: start 22, 10 bit, big-endian, init-value=400, base-type=uint16, compu {1023=Cx3FF_Faulty, phys=raw*0.125-50 for raw 0..1023; unit degrees/second} "Source signal range: [0,1022]", unit=degrees/second, transfer-property=PENDING, to PSCM_FD
          signal TrlrAid_An3_Actl_oTrailerAid_Stat3_FD1_oFD1_CAN: start 28, 11 bit, big-endian, init-value=720, base-type=uint16, compu {2047=Cx7FF_Faulty, phys=raw*0.125-90 for raw 0..2047; unit degrees} "Source signal range: [0,2046]", unit=degrees, transfer-property=PENDING, to PSCM_FD
          signal TrlrRvrse_D_Stat_oTrailerAid_Stat3_FD1_oFD1_CAN: start 42, 2 bit, big-endian, init-value=0, base-type=uint8, compu {0..3=RANGE, 0=Cx0_Off, 1=Cx1_On, 2=Cx2_TrailerReverseGuidanceLite, 3=Cx3_Faulty; unit SED}, unit=SED, transfer-property=PENDING, to PSCM_FD
          signal TrlrAidTrgtId_No_Actl_oTrailerAid_Stat3_FD1_oFD1_CAN: start 47, 5 bit, big-endian, init-value=0, base-type=uint8, compu {0..31=RANGE; unit unitless}, unit=unitless, transfer-property=PENDING, to PSCM_FD
          signal TrlrTrgtAcquire_D_Stat_oTrailerAid_Stat3_FD1_oFD1_CAN: start 51, 3 bit, big-endian, init-value=0, base-type=uint8, compu {0..7=RANGE, 0=Cx0_Null, 1=Cx1_TargetAcquired, 2=Cx2_TargetNotAcquired, 3=Cx3_Processing, 4=Cx4_RVCforTBA_Activated, 5=Cx5_NotUsed_1, 6=Cx6_NotUsed_2, 7=Cx7_Faulty; unit SED}, unit=SED, transfer-property=PENDING, to PSCM_FD
          signal TrlrAid_D2_Stat_oTrailerAid_Stat3_FD1_oFD1_CAN: start 55, 4 bit, big-endian, init-value=0, base-type=uint8, compu {0..15=RANGE, 0=Cx0_NotTracking, 1=Cx1_Initializing, 2=Cx2_DriveStraighRequested, 3=Cx3_TurnRequested, 4=Cx4_TrackingLowConfidence, 5=Cx5_TrackingMediumConfidence, 6=Cx6_TrackingHighConfidence, 7=Cx7_TrackingUnknownConfidence, 8=Cx8_TrackingLost, 9=Cx9_IncorrectLighting, 10=CxA_DirtyCamera, 11=CxB_NotUsed_1, 12=CxC_NotUsed_2, 13=CxD_NotUsed_3, 14=CxE_NotUsed_4, 15=CxF_Faulty; unit SED}, unit=SED, transfer-property=PENDING, to PSCM_FD
      frame TrailerBrakeInfo_FD1_oFD1_CAN: id 0x445, to PSCM_FD, frame-length=8, can-addressing-mode=STANDARD, can-frame-rx-behavior=ANY, can-frame-tx-behavior=CAN-FD
        pdu TrailerBrakeInfo_FD1_oFD1_CAN: length=8, minimum-delay=0.02, unused-bit-pattern=0
          signal TrlrBrkActCnnct_B_Actl_oTrailerBrakeInfo_FD1_oFD1_CAN: start 6, 1 bit, big-endian, init-value=0, base-type=boolean, compu {0..1=RANGE, 0=Cx0_No, 1=Cx1_Yes; unit SED}, unit=SED, transfer-property=PENDING, to PSCM_FD
      frame TrailerInfo_2_FD1_oFD1_CAN: id 0x47A, to PSCM_FD, frame-length=8, can-addressing-mode=STANDARD, can-frame-rx-behavior=ANY, can-frame-tx-behavior=CAN-FD
        pdu TrailerInfo_2_FD1_oFD1_CAN: length=8, minimum-delay=0.02, unused-bit-pattern=0
          signal TrlrAidCtl_U_RqDrv_oTrailerInfo_2_FD1_oFD1_CAN: start 31, 12 bit, big-endian, init-value=4094, base-type=uint16, compu {4094=CxFFE_NoDataExists, 4095=CxFFF_Faulty, phys=raw/800 for raw 0..4095; unit volt} "Source signal range: [0,4093]", unit=volt, transfer-property=PENDING, to PSCM_FD
          signal TrlrAidSwtch_D_RqDrv_oTrailerInfo_2_FD1_oFD1_CAN: start 35, 2 bit, big-endian, init-value=0, base-type=uint8, compu {0..3=RANGE, 0=Cx0_Not_Pressed, 1=Cx1_Pressed, 2=Cx2_NotUsed, 3=Cx3_Faulty; unit SED}, unit=SED, transfer-property=PENDING, to PSCM_FD
      frame TrailerInfo_FD1_oFD1_CAN: id 0x443, to PSCM_FD, frame-length=8, can-addressing-mode=STANDARD, can-frame-rx-behavior=ANY, can-frame-tx-behavior=CAN-FD
        pdu TrailerInfo_FD1_oFD1_CAN: length=8, minimum-delay=0.02, unused-bit-pattern=0
          signal TrlrLampCnnct_B_Actl_oTrailerInfo_FD1_oFD1_CAN: start 7, 1 bit, big-endian, init-value=0, base-type=boolean, compu {0..1=RANGE, 0=Cx0_No, 1=Cx1_Yes; unit SED}, unit=SED, transfer-property=PENDING, to PSCM_FD
      frame TransGearData_FD1_oFD1_CAN: id 0x230, to PSCM_FD, frame-length=8, can-addressing-mode=STANDARD, can-frame-rx-behavior=ANY, can-frame-tx-behavior=CAN-FD  # MHT (U611/625) the HPCM will Rx 0x230 from the PCM_HEV Powersplit FWD HEVs (Cx482/3 430) the HPCM will Tx 0x230
        pdu TransGearData_FD1_oFD1_CAN: length=8, minimum-delay=0.01, transmission-mode-false-timing=cyclic-timing={time-offset=0, time-period=0.02}, transmission-mode-true-timing=cyclic-timing={time-offset=0, time-period=0.02}, unused-bit-pattern=0
          signal GearLvrPos_D_Actl_oTransGearData_FD1_oFD1_CAN: start 12, 4 bit, big-endian, init-value=14, base-type=uint8, compu {0..15=RANGE, 0=Cx0_Park, 1=Cx1_Reverse, 2=Cx2_Neutral, 3=Cx3_Drive, 4=Cx4_Sport_DriveSport, 5=Cx5_Low, 6=Cx6_first, 7=Cx7_second, 8=Cx8_third, 9=Cx9_fourth, 10=CxA_fifth, 11=CxB_sixth, 12=CxC_Undefined_Treat_as_Fault, 13=CxD_Undefined_Treat_as_Fault (Undefined_Treat_as__Fault), 14=CxE_Unknown_Position, 15=CxF_Fault; unit SED}, unit=SED, transfer-property=PENDING, to PSCM_FD
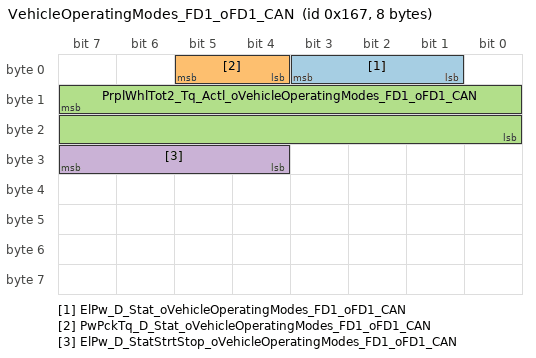
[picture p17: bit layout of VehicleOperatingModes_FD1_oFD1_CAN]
      frame VehicleOperatingModes_FD1_oFD1_CAN: id 0x167, to PSCM_FD, frame-length=8, can-addressing-mode=STANDARD, can-frame-rx-behavior=ANY, can-frame-tx-behavior=CAN-FD
        pdu VehicleOperatingModes_FD1_oFD1_CAN: length=8, minimum-delay=0, transmission-mode-false-timing=cyclic-timing={time-offset=0, time-period=0.01}, transmission-mode-true-timing=cyclic-timing={time-offset=0, time-period=0.01}, unused-bit-pattern=0
          signal ElPw_D_Stat_oVehicleOperatingModes_FD1_oFD1_CAN: start 3, 3 bit, big-endian, init-value=0, base-type=uint8, compu {0..7=RANGE, 0=Cx0_Not_Supported, 1=Cx1_Supported, 2=Cx2_Not_Supported_Imminent, 3=Cx3_LV_Event_In_Progress, 4=Cx4_Fault_Limited, 5=Cx5_NotUsed_1, 6=Cx6_NotUsed_2, 7=Cx7_NotUsed_3; unit SED}, unit=SED, transfer-property=PENDING, to PSCM_FD
          signal PwPckTq_D_Stat_oVehicleOperatingModes_FD1_oFD1_CAN: start 5, 2 bit, big-endian, init-value=0, base-type=uint8, compu {0..3=RANGE, 0=Cx0_PwPckOff_TqNotAvailable, 1=Cx1_PwPckOn_TqNotAvailable, 2=Cx2_StartInPrgrss_TqNotAvail, 3=Cx3_PwPckOn_TqAvailable; unit SED}, unit=SED, transfer-property=PENDING, to PSCM_FD
          signal PrplWhlTot2_Tq_Actl_oVehicleOperatingModes_FD1_oFD1_CAN: start 15, 16 bit, big-endian, init-value=0, base-type=uint16, compu {65534=CxFFFE_NoDataExists, 65535=CxFFFF_Fault, phys=raw*4-131072 for raw 0..65535; unit Nm} "Source signal range: [0,65533]", unit=Nm, transfer-property=PENDING, to PSCM_FD
          signal ElPw_D_StatStrtStop_oVehicleOperatingModes_FD1_oFD1_CAN: start 31, 4 bit, big-endian, init-value=0, base-type=uint8, compu {0..15=RANGE, 0=Cx0_Not_Supported, 1=Cx1_Supported_All, 2=Cx2_Not_Supported_Imminent, 3=Cx3_LV_Event_in_Progress, 4=Cx4_Fault_Limited, 5=Cx5_Limited_Support, 6=Cx6_Supported_Level_1, 7=Cx7_Supported_Level_2, 8=Cx8_Supported_Level_3, 9=Cx9_Supported_Level_4, 10=CxA_NotUsed1, 11=CxB_NotUsed2, 12=CxC_NotUsed3, 13=CxD_NotUsed4, 14=CxE_NotUsed5, 15=CxF_NotUsed6; unit SED}, unit=SED, transfer-property=PENDING, to PSCM_FD
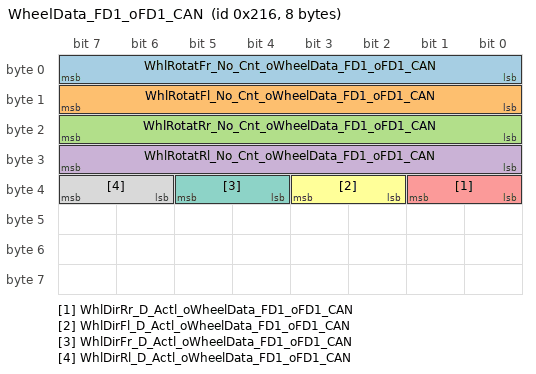
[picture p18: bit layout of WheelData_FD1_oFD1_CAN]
      frame WheelData_FD1_oFD1_CAN: id 0x216, to PSCM_FD, frame-length=8, can-addressing-mode=STANDARD, can-frame-rx-behavior=ANY, can-frame-tx-behavior=CAN-FD
        pdu WheelData_FD1_oFD1_CAN: length=8, minimum-delay=0.01, transmission-mode-false-timing=cyclic-timing={time-offset=0, time-period=0.02}, transmission-mode-true-timing=cyclic-timing={time-offset=0, time-period=0.02}, unused-bit-pattern=0
          signal WhlRotatFr_No_Cnt_oWheelData_FD1_oFD1_CAN: start 7, 8 bit, big-endian, init-value=0, base-type=uint8, compu {0..255=RANGE; unit Unitless}, unit=Unitless, transfer-property=PENDING, to PSCM_FD  # DCR 1833 to update Tx from GWM to EP100ms. Wheel Count signals are used by complex algorithm to determine Tire Pressure by Location & can't change from 20msec. (jweinfur)
          signal WhlRotatFl_No_Cnt_oWheelData_FD1_oFD1_CAN: start 15, 8 bit, big-endian, init-value=0, base-type=uint8, compu {0..255=RANGE; unit Unitless}, unit=Unitless, transfer-property=PENDING, to PSCM_FD  # DCR 1833 to update Tx from GWM to EP100ms. Wheel Count signals are used by complex algorithm to determine Tire Pressure by Location & can't change from 20msec. (jweinfur)
          signal WhlRotatRr_No_Cnt_oWheelData_FD1_oFD1_CAN: start 23, 8 bit, big-endian, init-value=0, base-type=uint8, compu {0..255=RANGE; unit Unitless}, unit=Unitless, transfer-property=PENDING, to PSCM_FD  # DCR 1833 to update Tx from GWM to EP100ms. Wheel Count signals are used by complex algorithm to determine Tire Pressure by Location & can't change from 20msec. (jweinfur)
          signal WhlRotatRl_No_Cnt_oWheelData_FD1_oFD1_CAN: start 31, 8 bit, big-endian, init-value=0, base-type=uint8, compu {0..255=RANGE; unit Unitless}, unit=Unitless, transfer-property=PENDING, to PSCM_FD  # DCR 1833 to update Tx from GWM to EP100ms. Wheel Count signals are used by complex algorithm to determine Tire Pressure by Location & can't change from 20msec. (jweinfur)
          signal WhlDirRr_D_Actl_oWheelData_FD1_oFD1_CAN: start 33, 2 bit, big-endian, init-value=0, base-type=uint8, compu {0..3=RANGE, 0=Cx0_Forward, 1=Cx1_Backward, 2=Cx2_Unknown, 3=Cx3_Failed; unit SED}, unit=SED, transfer-property=PENDING, to PSCM_FD
          signal WhlDirFl_D_Actl_oWheelData_FD1_oFD1_CAN: start 35, 2 bit, big-endian, init-value=0, base-type=uint8, compu {0..3=RANGE, 0=Cx0_Forward, 1=Cx1_Backward, 2=Cx2_Unknown, 3=Cx3_Failed; unit SED}, unit=SED, transfer-property=PENDING, to PSCM_FD
          signal WhlDirFr_D_Actl_oWheelData_FD1_oFD1_CAN: start 37, 2 bit, big-endian, init-value=0, base-type=uint8, compu {0..3=RANGE, 0=Cx0_Forward, 1=Cx1_Backward, 2=Cx2_Unknown, 3=Cx3_Failed; unit SED}, unit=SED, transfer-property=PENDING, to PSCM_FD
          signal WhlDirRl_D_Actl_oWheelData_FD1_oFD1_CAN: start 39, 2 bit, big-endian, init-value=0, base-type=uint8, compu {0..3=RANGE, 0=Cx0_Forward, 1=Cx1_Backward, 2=Cx2_Unknown, 3=Cx3_Failed; unit SED}, unit=SED, transfer-property=PENDING, to PSCM_FD
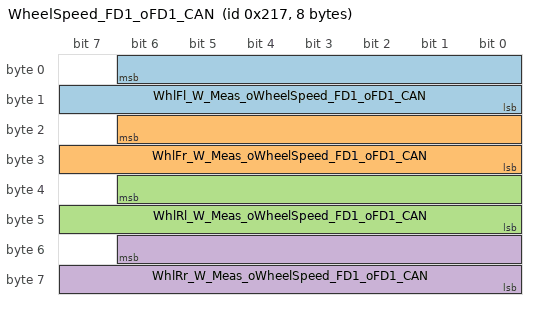
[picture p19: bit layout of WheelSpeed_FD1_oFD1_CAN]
      frame WheelSpeed_FD1_oFD1_CAN: id 0x217, to PSCM_FD, frame-length=8, can-addressing-mode=STANDARD, can-frame-rx-behavior=ANY, can-frame-tx-behavior=CAN-FD
        pdu WheelSpeed_FD1_oFD1_CAN: length=8, minimum-delay=0, transmission-mode-false-timing=cyclic-timing={time-offset=0, time-period=0.01}, transmission-mode-true-timing=cyclic-timing={time-offset=0, time-period=0.01}, unused-bit-pattern=0
          signal WhlFl_W_Meas_oWheelSpeed_FD1_oFD1_CAN: start 6, 15 bit, big-endian, init-value=0, base-type=uint16, compu {32766=Cx7FFE_Unknown, 32767=Cx7FFF_Fault, phys=raw*0.01 for raw 0..32767; unit rad/s} "Source signal range: [0,32765]", unit=rad/s, transfer-property=PENDING, to PSCM_FD
          signal WhlFr_W_Meas_oWheelSpeed_FD1_oFD1_CAN: start 22, 15 bit, big-endian, init-value=0, base-type=uint16, compu {32766=Cx7FFE_Unknown, 32767=Cx7FFF_Fault, phys=raw*0.01 for raw 0..32767; unit rad/s} "Source signal range: [0,32765]", unit=rad/s, transfer-property=PENDING, to PSCM_FD
          signal WhlRl_W_Meas_oWheelSpeed_FD1_oFD1_CAN: start 38, 15 bit, big-endian, init-value=0, base-type=uint16, compu {32766=Cx7FFE_Unknown, 32767=Cx7FFF_Fault, phys=raw*0.01 for raw 0..32767; unit rad/s} "Source signal range: [0,32765]", unit=rad/s, transfer-property=PENDING, to PSCM_FD
          signal WhlRr_W_Meas_oWheelSpeed_FD1_oFD1_CAN: start 54, 15 bit, big-endian, init-value=0, base-type=uint16, compu {32766=Cx7FFE_Unknown, 32767=Cx7FFF_Fault, phys=raw*0.01 for raw 0..32767; unit rad/s} "Source signal range: [0,32765]", unit=rad/s, transfer-property=PENDING, to PSCM_FD
      frame Xcp_CRO_Msg_oFD1_CAN: id 0x60A, to PSCM_FD, frame-length=8, variation-point=post-build-variant-condition{matching-criterion=Communication, value=0}, can-addressing-mode=STANDARD, can-frame-rx-behavior=ANY, can-frame-tx-behavior=CAN-20  # drecker 10/23/09 Need SAPP in sync w/Strg Torque for proper PAM interpretation, else fault msg's displayed FP@20ms IPC needs EPAS_Failure for msg to driver. Not map w/Lane Assist FP@30s FP), save bandwidth if feature not on vehicle
        xcp pdu Xcp_CRO_Msg_oFD1_CAN: length=8
      frame Xcp_DTO_Msg_oFD1_CAN: id 0x60B, from PSCM_FD, frame-length=8, variation-point=post-build-variant-condition{matching-criterion=Communication, value=0}, can-addressing-mode=STANDARD, can-frame-rx-behavior=ANY, can-frame-tx-behavior=CAN-20  # drecker 10/23/09 Need SAPP in sync w/Strg Torque for proper PAM interpretation, else fault msg's displayed FP@20ms IPC needs EPAS_Failure for msg to driver. Not map w/Lane Assist FP@30s FP), save bandwidth if feature not on vehicle
        xcp pdu Xcp_DTO_Msg_oFD1_CAN: length=8
      frame Yaw_Data_FD1_oFD1_CAN: id 0x91, to PSCM_FD, frame-length=8, can-addressing-mode=STANDARD, can-frame-rx-behavior=ANY, can-frame-tx-behavior=CAN-FD
        pdu Yaw_Data_FD1_oFD1_CAN: length=8, minimum-delay=0.02, unused-bit-pattern=0
          signal VehYaw_W_Actl_oYaw_Data_FD1_oFD1_CAN: start 23, 16 bit, big-endian, init-value=65534, base-type=uint16, compu {65534=CxFFFE_NoDataExists, 65535=CxFFFF_Faulty, phys=raw*0.0002-6.5 for raw 0..65535; unit rad/s} "Source signal range: [0,65533]", unit=rad/s, transfer-property=PENDING, to PSCM_FD  # CCMGenSigTimeoutTime=1000
      frame EPAS_INFO_FD1_oFD1_CAN: id 0x182, from PSCM_FD, frame-length=8, variation-point=post-build-variant-condition{matching-criterion=Communication, value=1}, can-addressing-mode=STANDARD, can-frame-rx-behavior=ANY, can-frame-tx-behavior=CAN-FD  # drecker 10/23/09 Need SAPP in sync w/Strg Torque for proper PAM interpretation, else fault msg's displayed FP@20ms IPC needs EPAS_Failure for msg to driver. Not map w/Lane Assist FP@30s FP), save bandwidth if feature not on vehicle
        carries pdu EPAS_INFO_FD1_oFD1_CAN: packing-byte-order=little-endian, start-position=0
      frame Lane_Assist_Data3_FD1_oFD1_CAN: id 0x4CC, from PSCM_FD, frame-length=8, variation-point=post-build-variant-condition{matching-criterion=Communication, value=1}, can-addressing-mode=STANDARD, can-frame-rx-behavior=ANY, can-frame-tx-behavior=CAN-FD
        carries pdu Lane_Assist_Data3_FD1_oFD1_CAN: packing-byte-order=little-endian, start-position=0
      frame PSCM_AutoSar_NetwrkMgt_FD1_oFD1_CAN: id 0x6B5, from PSCM_FD, frame-length=8, variation-point=post-build-variant-condition{matching-criterion=Communication, value=1}, can-addressing-mode=STANDARD, can-frame-rx-behavior=ANY, can-frame-tx-behavior=CAN-FD
        carries pdu PSCM_AutoSar_NetwrkMgt_FD1_oFD1_CAN: packing-byte-order=little-endian, start-position=0
      frame SteeringPinion_Data_FD1_oFD1_CAN: id 0x17E, from PSCM_FD, frame-length=8, variation-point=post-build-variant-condition{matching-criterion=Communication, value=1}, can-addressing-mode=STANDARD, can-frame-rx-behavior=ANY, can-frame-tx-behavior=CAN-FD
        carries pdu SteeringPinion_Data_FD1_oFD1_CAN: packing-byte-order=little-endian, start-position=0
      frame TesterFunctionalReq_FD1_oFD1_CAN: id 0x6DF, to PSCM_FD, frame-length=64, variation-point=post-build-variant-condition{matching-criterion=Communication, value=1}, can-addressing-mode=STANDARD, can-frame-rx-behavior=CAN-FD, can-frame-tx-behavior=CAN-FD  # OBDII Request ($7DF) messages are for FNOS 1.0.1 only. Diagnostic Functional Addressing ($7DF) and Dual Rate Periodic messages are for FNOS I3 only.
        carries pdu TesterFunctionalReq_FD1_Tp_oFD1_CAN: packing-byte-order=little-endian, start-position=0
      frame TesterFunctionalReq_FD1_oFD1_CAN_20: id 0x6DF, to PSCM_FD, frame-length=8, variation-point=post-build-variant-condition{matching-criterion=Communication, value=1}, can-addressing-mode=STANDARD, can-frame-rx-behavior=CAN-20, can-frame-tx-behavior=CAN-20
        carries pdu TesterFunctionalReq_FD1_Tp_oFD1_CAN_20: packing-byte-order=little-endian, start-position=0
      frame TesterPhysicalReqPSCM_FD1_oFD1_CAN: id 0x65E, to PSCM_FD, frame-length=64, variation-point=post-build-variant-condition{matching-criterion=Communication, value=1}, can-addressing-mode=STANDARD, can-frame-rx-behavior=CAN-FD, can-frame-tx-behavior=CAN-FD
        carries pdu TesterPhysicalReqPSCM_FD1_Tp_oFD1_CAN: packing-byte-order=little-endian, start-position=0
      frame TesterPhysicalReqPSCM_FD1_oFD1_CAN_20: id 0x65E, to PSCM_FD, frame-length=8, variation-point=post-build-variant-condition{matching-criterion=Communication, value=1}, can-addressing-mode=STANDARD, can-frame-rx-behavior=CAN-20, can-frame-tx-behavior=CAN-20
        carries pdu TesterPhysicalReqPSCM_FD1_Tp_oFD1_CAN_20: packing-byte-order=little-endian, start-position=0
      frame TesterPhysicalResPSCM_FD1_oFD1_CAN: id 0x65F, from PSCM_FD, frame-length=64, variation-point=post-build-variant-condition{matching-criterion=Communication, value=1}, can-addressing-mode=STANDARD, can-frame-rx-behavior=CAN-FD, can-frame-tx-behavior=CAN-FD
        carries pdu TesterPhysicalResPSCM_FD1_Tp_oFD1_CAN: packing-byte-order=little-endian, start-position=0
      frame TesterPhysicalResPSCM_FD1_oFD1_CAN_20: id 0x65F, from PSCM_FD, frame-length=8, variation-point=post-build-variant-condition{matching-criterion=Communication, value=1}, can-addressing-mode=STANDARD, can-frame-rx-behavior=CAN-20, can-frame-tx-behavior=CAN-20
        carries pdu TesterPhysicalResPSCM_FD1_Tp_oFD1_CAN_20: packing-byte-order=little-endian, start-position=0
      frame TrailerAid_Data2_FD1_oFD1_CAN: id 0x517, from PSCM_FD, frame-length=8, variation-point=post-build-variant-condition{matching-criterion=Communication, value=1}, can-addressing-mode=STANDARD, can-frame-rx-behavior=ANY, can-frame-tx-behavior=CAN-FD
        carries pdu TrailerAid_Data2_FD1_oFD1_CAN: packing-byte-order=little-endian, start-position=0
      frame Xcp_CRO_Msg_oFD1_CAN: id 0x660, to PSCM_FD, frame-length=8, variation-point=post-build-variant-condition{matching-criterion=Communication, value=1}, can-addressing-mode=STANDARD, can-frame-rx-behavior=ANY, can-frame-tx-behavior=CAN-20  # drecker 10/23/09 Need SAPP in sync w/Strg Torque for proper PAM interpretation, else fault msg's displayed FP@20ms IPC needs EPAS_Failure for msg to driver. Not map w/Lane Assist FP@30s FP), save bandwidth if feature not on vehicle
        carries pdu Xcp_CRO_Msg_oFD1_CAN: packing-byte-order=little-endian, start-position=0
      frame Xcp_DTO_Msg_oFD1_CAN: id 0x661, from PSCM_FD, frame-length=8, variation-point=post-build-variant-condition{matching-criterion=Communication, value=1}, can-addressing-mode=STANDARD, can-frame-rx-behavior=ANY, can-frame-tx-behavior=CAN-20  # drecker 10/23/09 Need SAPP in sync w/Strg Torque for proper PAM interpretation, else fault msg's displayed FP@20ms IPC needs EPAS_Failure for msg to driver. Not map w/Lane Assist FP@30s FP), save bandwidth if feature not on vehicle
        carries pdu Xcp_DTO_Msg_oFD1_CAN: packing-byte-order=little-endian, start-position=0
      pdu triggering PT_DeliveryVersion: pdu=DeliveryVersion_oFD1_CAN, to PSCM_FD
      pdu triggering PT_FileVersion: pdu=FileVersion_oFD1_CAN, to PSCM_FD
      pdu triggering PT_TesterFunctionalReq_FD1: pdu=TesterFunctionalReq_FD1_oFD1_CAN, to PSCM_FD
      pdu triggering PT_TesterFunctionalReq_FD1_20: pdu=TesterFunctionalReq_FD1_oFD1_CAN_20, to PSCM_FD
      pdu triggering PT_TesterPhysicalReqPSCM_FD1: pdu=TesterPhysicalReqPSCM_FD1_oFD1_CAN, to PSCM_FD
      pdu triggering PT_TesterPhysicalReqPSCM_FD1_20: pdu=TesterPhysicalReqPSCM_FD1_oFD1_CAN_20, to PSCM_FD
      pdu triggering PT_TesterPhysicalResPSCM_FD1: pdu=TesterPhysicalResPSCM_FD1_oFD1_CAN, from PSCM_FD
      pdu triggering PT_TesterPhysicalResPSCM_FD1_20: pdu=TesterPhysicalResPSCM_FD1_oFD1_CAN_20, from PSCM_FD
package /ECU
  ecu instance PSCM_FD: associated-com-i-pdu-group=[PSCM_FD_oFD1_CAN_Rx, PSCM_FD_oFD1_CAN_Tx]  # Passenger Front Climate Control Seat Module
    can communication controller CT_FD1_CAN
    can communication connector CN_FD1_CAN: comm-controller=CT_FD1_CAN
package /IPDUGroup
  i signal i pdu group PSCM_FD_oFD1_CAN_Rx: communication-direction=IN
    i-signal-i-pdus:
      ABS_BrkBst_Data_FD1_oFD1_CAN
      ActiveFrontStrg_Stat2_FD1_oFD1_CAN
      APIM_Send_Signals_2_FD1_oFD1_CAN
      APIM_Send_Signals1_FD1_oFD1_CAN
      Body_Info_4_FD1_oFD1_CAN
      BodyInfo_3_FD1_oFD1_CAN
      BrakeSnData_{3..6}_FD1_oFD1_CAN
      BrakeSysFeatures_3_oFD1_CAN
      BrakeSysFeatures_FD1_oFD1_CAN
      Climate_Control_Data_FD1_oFD1_CAN
      Cluster_Info1_FD1_oFD1_CAN
      DeliveryVersion_oFD1_CAN
      DesiredTorqBrk_FD1_oFD1_CAN
      EngBrakeData_FD1_oFD1_CAN
      EngVehicleSpThrottle_FD1_oFD1_CAN
      EngVehicleSpThrottle2_FD1_oFD1_CAN
      FileVersion_oFD1_CAN
      GGCC_Config_Mgmt_ID_1_FD1_oFD1_CAN
      Image_Processing_Data_FD1_oFD1_CAN
      Lane_Assist_Data1_FD1_oFD1_CAN
      LateralMotionControl_FD1_oFD1_CAN
      Mc_Send_Signals_2_FD1_oFD1_CAN
      ParkAid_Data_FD1_oFD1_CAN
      PowertrainData_10_FD1_oFD1_CAN
      Steer_Assist_Data_FD1_oFD1_CAN
      Steering_Data_FD1_oFD1_CAN
      TrailerAid_Data_FD1_oFD1_CAN
      TrailerAid_Data3_FD1_oFD1_CAN
      TrailerAid_Stat{1..3}_FD1_oFD1_CAN
      TrailerBrakeInfo_FD1_oFD1_CAN
      TrailerInfo_2_FD1_oFD1_CAN
      TrailerInfo_FD1_oFD1_CAN
      TransGearData_FD1_oFD1_CAN
      VehicleOperatingModes_FD1_oFD1_CAN
      WheelData_FD1_oFD1_CAN
      WheelSpeed_FD1_oFD1_CAN
      Yaw_Data_FD1_oFD1_CAN
  i signal i pdu group PSCM_FD_oFD1_CAN_Tx: communication-direction=OUT
    i-signal-i-pdus:
      EPAS_INFO_FD1_oFD1_CAN
      Lane_Assist_Data3_FD1_oFD1_CAN
      SteeringPinion_Data_FD1_oFD1_CAN
      TrailerAid_Data2_FD1_oFD1_CAN
package /PDU
  pdu DeliveryVersion_oFD1_CAN: length=10, unused-bit-pattern=0
    signal DeliverySipNumber_oDeliveryVersion_oFD1_CAN: start 0, 24 bit, little-endian, init-value=1507332, base-type=uint32, to PSCM_FD
    signal DeliverySubProjectNumber_oDeliveryVersion_oFD1_CAN: start 24, 32 bit, little-endian, init-value=23072854, base-type=uint32, to PSCM_FD
    signal DeliveryNumber_oDeliveryVersion_oFD1_CAN: start 56, 8 bit, little-endian, init-value=0, base-type=uint8, to PSCM_FD
    signal DeliveryIdle_oDeliveryVersion_oFD1_CAN: start 64, 16 bit, little-endian, init-value=0, base-type=uint16, to PSCM_FD
  pdu FileVersion_oFD1_CAN: length=4, unused-bit-pattern=0
    signal FileVersionYear_oFileVersion_oFD1_CAN: start 0, 8 bit, little-endian, init-value=23, base-type=uint8, to PSCM_FD
    signal FileVersionMonth_oFileVersion_oFD1_CAN: start 8, 8 bit, little-endian, init-value=17, base-type=uint8, to PSCM_FD
    signal FileVersionDay_oFileVersion_oFD1_CAN: start 16, 8 bit, little-endian, init-value=48, base-type=uint8, to PSCM_FD
    signal FileVersionNumber_oFileVersion_oFD1_CAN: start 24, 8 bit, little-endian, init-value=5, base-type=uint8, to PSCM_FD
  dcm i pdu TesterFunctionalReq_FD1_oFD1_CAN: length=62, diag-pdu-type=DIAG-REQUEST
  dcm i pdu TesterFunctionalReq_FD1_oFD1_CAN_20: length=7, diag-pdu-type=DIAG-REQUEST
  dcm i pdu TesterPhysicalReqPSCM_FD1_oFD1_CAN: length=64, diag-pdu-type=DIAG-REQUEST
  dcm i pdu TesterPhysicalReqPSCM_FD1_oFD1_CAN_20: length=8, diag-pdu-type=DIAG-REQUEST
  dcm i pdu TesterPhysicalResPSCM_FD1_oFD1_CAN: length=64, diag-pdu-type=DIAG-RESPONSE
  dcm i pdu TesterPhysicalResPSCM_FD1_oFD1_CAN_20: length=8, diag-pdu-type=DIAG-RESPONSE
package /DataType
  base type uint8_6_iso_8859_1: category=FIXED_LENGTH, base-type-size=48, base-type-encoding=ISO-8859-1
  base type uint8_8_iso_8859_1: category=FIXED_LENGTH, base-type-size=64, base-type-encoding=ISO-8859-1
package /DataType/Unit
  29 x unit:
    U_1Ym: display-name=1/m
    U_1Ymeter: display-name=1/meter
    U_Amps: display-name=Amps
    U_deg: display-name=deg
    U_degrees: display-name=degrees
    U_Degrees: display-name=Degrees
    U_Degrees_C: display-name=Degrees C
    U_degreesYsecond: display-name=degrees/second
    U_degYs: display-name=deg/s
    U_km: display-name=km
    U_kmYh: display-name=km/h
    U_kph: display-name=kph
    U_meter: display-name=meter
    U_metersYsec: display-name=meters/sec
    U_mixed: display-name=mixed
    U_mrad: display-name=mrad
    U_mYsX2: display-name=m/s^2
    U_Nm: display-name=Nm
    U_p: display-name=%
    U_radians: display-name=radians
    U_radiansYsecond: display-name=radians/second
    U_radYs: display-name=rad/s
    U_rpm: display-name=rpm
    U_second: display-name=second
    U_SED: display-name=SED
    U_volt: display-name=volt
    U_Volts: display-name=Volts
    unitless: display-name=unitless
    Unitless: display-name=Unitless
